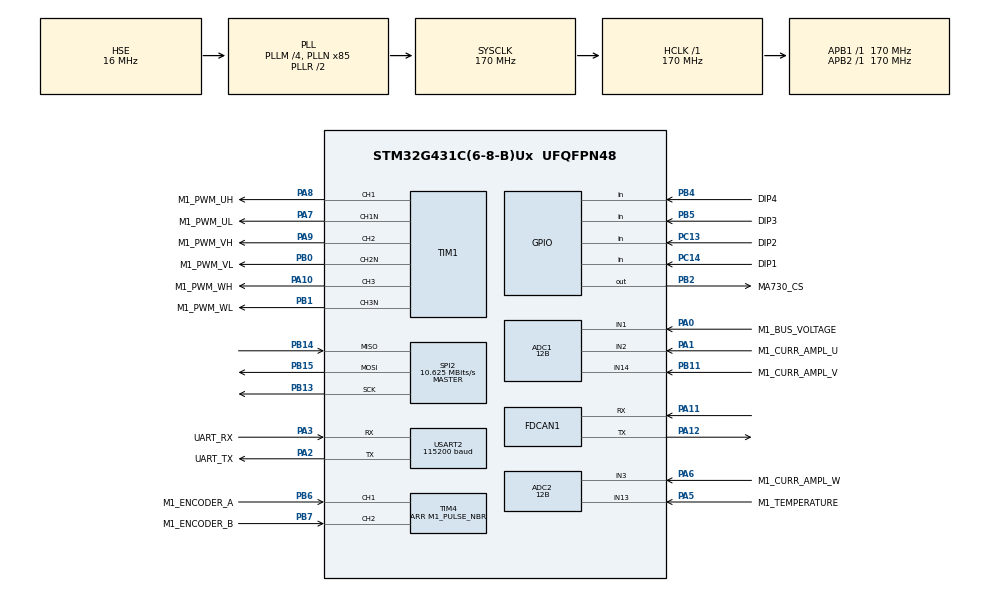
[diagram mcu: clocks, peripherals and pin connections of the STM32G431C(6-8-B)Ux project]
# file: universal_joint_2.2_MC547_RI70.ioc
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ADC1.Channel-1\#ChannelRegularConversion=ADC_CHANNEL_1
ADC1.ClockPrescaler=ADC_CLOCK_ASYNC_DIV4
ADC1.ContinuousConvMode=DISABLE
ADC1.DMAContinuousRequests=DISABLE
ADC1.DataAlign=ADC_DATAALIGN_LEFT
ADC1.DiscontinuousConvMode=DISABLE
ADC1.EOCSelection=ADC_EOC_SINGLE_CONV
ADC1.EnableAnalogWatchDog1=false
ADC1.EnableAnalogWatchDog2=false
ADC1.EnableAnalogWatchDog3=false
ADC1.EnableInjectedConversion=ENABLE
ADC1.EnableRegularConversion=ENABLE
ADC1.ExternalTrigConv=ADC_SOFTWARE_START
ADC1.ExternalTrigConvEdge=ADC_EXTERNALTRIGCONVEDGE_NONE
ADC1.ExternalTrigInjecConv=ADC_EXTERNALTRIGINJEC_T1_TRGO
ADC1.ExternalTrigInjecConvEdge=ADC_EXTERNALTRIGINJECCONV_EDGE_RISING
ADC1.InjNumberOfConversion=2
ADC1.InjectedChannel-1\#ChannelInjectedConversion=ADC_CHANNEL_2
ADC1.InjectedChannel-2\#ChannelInjectedConversion=ADC_CHANNEL_14
ADC1.InjectedConvMode=None
ADC1.InjectedOffset-1\#ChannelInjectedConversion=0
ADC1.InjectedOffset-2\#ChannelInjectedConversion=0
ADC1.InjectedOffsetNumber-1\#ChannelInjectedConversion=ADC_OFFSET_NONE
ADC1.InjectedOffsetNumber-2\#ChannelInjectedConversion=ADC_OFFSET_NONE
ADC1.InjectedRank-1\#ChannelInjectedConversion=1
ADC1.InjectedRank-2\#ChannelInjectedConversion=2
ADC1.InjectedSamplingTime-1\#ChannelInjectedConversion=ADC_SAMPLETIME_6CYCLES_5
ADC1.InjectedSamplingTime-2\#ChannelInjectedConversion=ADC_SAMPLETIME_6CYCLES_5
ADC1.LowPowerAutoWait=DISABLE
ADC1.NbrOfConversion=1
ADC1.NbrOfConversionFlag=1
ADC1.Offset-1\#ChannelRegularConversion=0
ADC1.OffsetNumber-1\#ChannelRegularConversion=ADC_OFFSET_NONE
ADC1.Overrun=ADC_OVR_DATA_PRESERVED
ADC1.Rank-1\#ChannelRegularConversion=1
ADC1.Resolution=ADC_RESOLUTION_12B
ADC1.SamplingTime-1\#ChannelRegularConversion=ADC_SAMPLETIME_47CYCLES_5
ADC1.ScanConvMode=ADC_SCAN_ENABLE
ADC1.master=1
ADC2.Channel-1\#ChannelRegularConversion=ADC_CHANNEL_13
ADC2.ClockPrescaler=ADC_CLOCK_ASYNC_DIV4
ADC2.ContinuousConvMode=DISABLE
ADC2.DMAContinuousRequests=DISABLE
ADC2.DataAlign=ADC_DATAALIGN_LEFT
ADC2.DiscontinuousConvMode=DISABLE
ADC2.EOCSelection=ADC_EOC_SINGLE_CONV
ADC2.EnableAnalogWatchDog1=false
ADC2.EnableAnalogWatchDog2=false
ADC2.EnableAnalogWatchDog3=false
ADC2.EnableInjectedConversion=ENABLE
ADC2.EnableRegularConversion=ENABLE
ADC2.ExternalTrigConv=ADC_SOFTWARE_START
ADC2.ExternalTrigConvEdge=ADC_EXTERNALTRIGCONVEDGE_NONE
ADC2.ExternalTrigInjecConv=ADC_EXTERNALTRIGINJEC_T1_TRGO
ADC2.ExternalTrigInjecConvEdge=ADC_EXTERNALTRIGINJECCONV_EDGE_RISING
ADC2.InjNumberOfConversion=2
ADC2.InjectedChannel-1\#ChannelInjectedConversion=ADC_CHANNEL_14
ADC2.InjectedChannel-2\#ChannelInjectedConversion=ADC_CHANNEL_3
ADC2.InjectedConvMode=None
ADC2.InjectedOffset-1\#ChannelInjectedConversion=0
ADC2.InjectedOffset-2\#ChannelInjectedConversion=0
ADC2.InjectedOffsetNumber-1\#ChannelInjectedConversion=ADC_OFFSET_NONE
ADC2.InjectedOffsetNumber-2\#ChannelInjectedConversion=ADC_OFFSET_NONE
ADC2.InjectedRank-1\#ChannelInjectedConversion=1
ADC2.InjectedRank-2\#ChannelInjectedConversion=2
ADC2.InjectedSamplingTime-1\#ChannelInjectedConversion=ADC_SAMPLETIME_6CYCLES_5
ADC2.InjectedSamplingTime-2\#ChannelInjectedConversion=ADC_SAMPLETIME_6CYCLES_5
ADC2.LowPowerAutoWait=DISABLE
ADC2.NbrOfConversion=1
ADC2.NbrOfConversionFlag=1
ADC2.Offset-1\#ChannelRegularConversion=0
ADC2.OffsetNumber-1\#ChannelRegularConversion=ADC_OFFSET_NONE
ADC2.Overrun=ADC_OVR_DATA_PRESERVED
ADC2.Rank-1\#ChannelRegularConversion=1
ADC2.Resolution=ADC_RESOLUTION_12B
ADC2.SamplingTime-1\#ChannelRegularConversion=ADC_SAMPLETIME_47CYCLES_5
ADC2.ScanConvMode=ADC_SCAN_ENABLE
ADC2.master=1
Dma.Request0=SPI2_RX
Dma.Request1=SPI2_TX
Dma.SPI2_RX.0.Direction=DMA_PERIPH_TO_MEMORY
Dma.SPI2_RX.0.EventEnable=DISABLE
Dma.SPI2_RX.0.Instance=DMA1_Channel1
Dma.SPI2_RX.0.MemDataAlignment=DMA_MDATAALIGN_HALFWORD
Dma.SPI2_RX.0.MemInc=DMA_MINC_ENABLE
Dma.SPI2_RX.0.Mode=DMA_NORMAL
Dma.SPI2_RX.0.PeriphDataAlignment=DMA_PDATAALIGN_HALFWORD
Dma.SPI2_RX.0.PeriphInc=DMA_PINC_DISABLE
Dma.SPI2_RX.0.Polarity=HAL_DMAMUX_REQ_GEN_RISING
Dma.SPI2_RX.0.Priority=DMA_PRIORITY_LOW
Dma.SPI2_RX.0.RequestNumber=1
Dma.SPI2_RX.0.SignalID=NONE
Dma.SPI2_RX.0.SyncEnable=DISABLE
Dma.SPI2_RX.0.SyncPolarity=HAL_DMAMUX_SYNC_NO_EVENT
Dma.SPI2_RX.0.SyncRequestNumber=1
Dma.SPI2_RX.0.SyncSignalID=NONE
Dma.SPI2_TX.1.Direction=DMA_MEMORY_TO_PERIPH
Dma.SPI2_TX.1.EventEnable=DISABLE
Dma.SPI2_TX.1.Instance=DMA1_Channel2
Dma.SPI2_TX.1.MemDataAlignment=DMA_MDATAALIGN_HALFWORD
Dma.SPI2_TX.1.MemInc=DMA_MINC_ENABLE
Dma.SPI2_TX.1.Mode=DMA_NORMAL
Dma.SPI2_TX.1.PeriphDataAlignment=DMA_PDATAALIGN_HALFWORD
Dma.SPI2_TX.1.PeriphInc=DMA_PINC_DISABLE
Dma.SPI2_TX.1.Polarity=HAL_DMAMUX_REQ_GEN_RISING
Dma.SPI2_TX.1.Priority=DMA_PRIORITY_LOW
Dma.SPI2_TX.1.RequestNumber=1
Dma.SPI2_TX.1.SignalID=NONE
Dma.SPI2_TX.1.SyncEnable=DISABLE
Dma.SPI2_TX.1.SyncPolarity=HAL_DMAMUX_SYNC_NO_EVENT
Dma.SPI2_TX.1.SyncRequestNumber=1
Dma.SPI2_TX.1.SyncSignalID=NONE
ExtraMW=MotorControl
ExtraMW.MotorControl.Config=MotorControl
ExtraMW.MotorControl.Mode=MotorControl
ExtraMW.MotorControl.Root=MCSDK_v5.4.7/MotorControl
ExtraMW.MotorControl.Template=templates
FDCAN1.AutoRetransmission=ENABLE
FDCAN1.ClockDivider=FDCAN_CLOCK_DIV2
FDCAN1.DataSyncJumpWidth=2
FDCAN1.DataTimeSeg1=12
FDCAN1.DataTimeSeg2=4
FDCAN1.FrameFormat=FDCAN_FRAME_FD_BRS
FDCAN1.NominalPrescaler=5
FDCAN1.NominalSyncJumpWidth=2
FDCAN1.NominalTimeSeg1=12
FDCAN1.NominalTimeSeg2=4
FDCAN1.StdFiltersNbr=2
FDCAN1.TransmitPause=ENABLE
Mcu.Family=STM32G4
Mcu.Name=STM32G431C(6-8-B)Ux
Mcu.Package=UFQFPN48
MotorControl.ADC_1_PERIPH=ADC1
MotorControl.ADC_2_PERIPH=ADC2
MotorControl.ADC_AHBPERIPH=RCC_AHBPeriph_ADC12
MotorControl.ADC_CLOCK_WB_DIV=4
MotorControl.ADC_CLOCK_WB_FREQ=42.5
MotorControl.ADC_PERIPH=ADC1
MotorControl.ADC_REFERENCE_VOLTAGE=3.30
MotorControl.ALIGNMENT_ANGLE_DEG=90
MotorControl.ALIGNMENT_DURATION=700
MotorControl.AMPLIFICATION_GAIN=5.00
MotorControl.ANGC={0,0,0,0,0,0,0,0}
MotorControl.BEMF_CONSISTENCY_GAIN=64
MotorControl.BEMF_CONSISTENCY_TOL=64
MotorControl.BKIN1_FILTER=0
MotorControl.BKIN2_FILTER=0
MotorControl.BKIN2_MODE=NONE
MotorControl.BKIN_MODE=NONE
MotorControl.BOARD=CUSTOM
MotorControl.BRKIN2_GPIO_AF=GPIO_AF_12
MotorControl.BRKIN_GPIO_AF=GPIO_AF_2
MotorControl.BUS_VOLTAGE_READING=true
MotorControl.CCMRAM_ENABLED=false
MotorControl.CLOCK_FREQUENCY=CPU_CLK_170_MHZ
MotorControl.CLOCK_SOURCE=EXTERNAL
MotorControl.CONSTANT1_D=500971
MotorControl.CONSTANT1_Q=500971
MotorControl.CONSTANT2_QD=39758
MotorControl.CORD_BEMF_CONSISTENCY_GAIN=64
MotorControl.CORD_BEMF_CONSISTENCY_TOL=64
MotorControl.CORD_F1=16384
MotorControl.CORD_F2=4096
MotorControl.CORD_FIFO_DEPTH_01HZ=64
MotorControl.CORD_FIFO_DEPTH_DPP=64
MotorControl.CORD_GAIN1=-24300
MotorControl.CORD_GAIN2=19853
MotorControl.CORD_MAX_ACCEL_DPPP=60
MotorControl.CORD_MEAS_ERRORS_BEFORE_FAULTS=3
MotorControl.CORD_VARIANCE_THRESHOLD=4
MotorControl.CPU_CLK_170_MHZ=true
MotorControl.CTRBDID=0
MotorControl.CUBE_MX_VER=6.3.0
MotorControl.CURRENT_READING_TOPOLOGY=THREE_SHUNT_INDEPENDENT_RESOURCES
MotorControl.CURR_SAMPLING_TIME=6
MotorControl.DAC_EMULATED=false
MotorControl.DAC_FUNCTIONALITY=false
MotorControl.DAC_TIMER_CH1_GPIO_PIN=LL_GPIO_PIN_0
MotorControl.DAC_TIMER_CH1_GPIO_PORT=GPIOA
MotorControl.DAC_TIMER_CH2_GPIO_PIN=LL_GPIO_PIN_0
MotorControl.DAC_TIMER_CH2_GPIO_PORT=GPIOA
MotorControl.DAC_TIMER_SELECTION=TIM3
MotorControl.DC_CURRENT_RS_MEAS=16.80
MotorControl.DEBUG_DAC_CH1=false
MotorControl.DEBUG_DAC_CH2=false
MotorControl.DEFAULT_CONTROL_MODE=STC_TORQUE_MODE
MotorControl.DEFAULT_DAC_CHANNEL_1=MC_PROTOCOL_REG_I_A
MotorControl.DEFAULT_DAC_CHANNEL_2=MC_PROTOCOL_REG_I_B
MotorControl.DEFAULT_DAC_MOTOR=0
MotorControl.DEFAULT_FLUX_COMPONENT=0
MotorControl.DEFAULT_TARGET_SPEED_RPM=1500
MotorControl.DEFAULT_TORQUE_COMPONENT=0
MotorControl.DISSIPATIVE_BRAKE_POLARITY=DOUT_ACTIVE_HIGH
MotorControl.DRIVES_NUMBER_SELECTION=SINGLEDRIVE
MotorControl.EMERGENCY2_STOP_GPIO_PIN=LL_GPIO_PIN_11
MotorControl.EMERGENCY2_STOP_GPIO_PORT=GPIOA
MotorControl.EMERGENCY_STOP_GPIO_PIN=LL_GPIO_PIN_11
MotorControl.EMERGENCY_STOP_GPIO_PORT=GPIOA
MotorControl.ENABLE_SL_ALGO_FROM_PHASE=3
MotorControl.ENCODER=true
MotorControl.ENCODER_AVAILABLE=true
MotorControl.ENCODER_PPR=3584
MotorControl.ENC_AVERAGING_FIFO_DEPTH=16
MotorControl.ENC_A_GPIO_PIN=LL_GPIO_PIN_6
MotorControl.ENC_A_GPIO_PORT=GPIOB
MotorControl.ENC_B_GPIO_PIN=LL_GPIO_PIN_7
MotorControl.ENC_B_GPIO_PORT=GPIOB
MotorControl.ENC_ICx_FILTER=128
MotorControl.ENC_INVERT_SPEED=false
MotorControl.ENC_MEAS_ERRORS_BEFORE_FAULTS=3
MotorControl.ENC_TIMER_REMAPPING=NO_REMAP_TIM4
MotorControl.ENC_TIMER_SELECTION=ENC_TIM4
MotorControl.ENC_USE_CH3=false
MotorControl.EXT_CLK_8_MHZ=true
MotorControl.EXT_CLOCK_FREQUENCY=EXT_CLK_8_MHZ
MotorControl.F1=16384
MotorControl.F2=4096
MotorControl.FEEDBACK_NET_FILTERING=false
MotorControl.FEED_FORWARD_CURRENT_REG_ENABLING=false
MotorControl.FINAL_I_ALIGNMENT=1936
MotorControl.FLUX_WEAKENING_ENABLING=false
MotorControl.FW_KIDIV=32768
MotorControl.FW_KI_GAIN=5000
MotorControl.FW_KPDIV=32768
MotorControl.FW_KP_GAIN=3000
MotorControl.FW_VOLTAGE_REF=985
MotorControl.GAIN1=-24300
MotorControl.GAIN2=19853
MotorControl.H1_GPIO_PIN=LL_GPIO_PIN_15
MotorControl.H1_GPIO_PORT=GPIOA
MotorControl.H2_GPIO_PIN=LL_GPIO_PIN_3
MotorControl.H2_GPIO_PORT=GPIOB
MotorControl.H3_GPIO_PIN=LL_GPIO_PIN_10
MotorControl.H3_GPIO_PORT=GPIOB
MotorControl.HALL_AVERAGING_FIFO_DEPTH=6
MotorControl.HALL_ICx_FILTER=255
MotorControl.HALL_MEAS_ERRORS_BEFORE_FAULTS=3
MotorControl.HALL_MTPA=false
MotorControl.HALL_PHASE_SHIFT=60
MotorControl.HALL_SENSORS_AVAILABLE=false
MotorControl.HALL_SENSORS_PLACEMENT=DEGREES_120
MotorControl.HALL_TIMER_REMAPPING=NO_REMAP_TIM2
MotorControl.HALL_TIMER_SELECTION=HALL_TIM2
MotorControl.HFI_AMPLITUDE=25
MotorControl.HFI_DC_0_COEFF=0.00146
MotorControl.HFI_DC_1_COEFF=0.002921
MotorControl.HFI_DC_2_COEFF=0.00146
MotorControl.HFI_DC_3_COEFF=1.889033
MotorControl.HFI_DC_4_COEFF=-0.894874
MotorControl.HFI_DEBUG_MODE=false
MotorControl.HFI_FREQUENCY=400
MotorControl.HFI_HIFRAMPLSCAN=25
MotorControl.HFI_HP_ID_0_COEFF=0.959381
MotorControl.HFI_HP_ID_1_COEFF=-1.918761
MotorControl.HFI_HP_ID_2_COEFF=0.959381
MotorControl.HFI_HP_ID_3_COEFF=1.917111
MotorControl.HFI_HP_ID_4_COEFF=-0.920412
MotorControl.HFI_IDH_DELAY=32400
MotorControl.HFI_LOCKFREQ=22
MotorControl.HFI_LP_ID_0_COEFF=0.002751
MotorControl.HFI_LP_ID_1_COEFF=0.005502
MotorControl.HFI_LP_ID_2_COEFF=0.002751
MotorControl.HFI_LP_ID_3_COEFF=1.846252
MotorControl.HFI_LP_ID_4_COEFF=-0.857255
MotorControl.HFI_MAXANGLEDIFF=3640
MotorControl.HFI_MINIMUM_SPEED_RPM=402
MotorControl.HFI_NOTCH_IQD_0_COEFF=0.979509
MotorControl.HFI_NOTCH_IQD_1_COEFF=-1.952148
MotorControl.HFI_NOTCH_IQD_2_COEFF=0.979509
MotorControl.HFI_NOTCH_IQD_3_COEFF=1.952148
MotorControl.HFI_NOTCH_IQD_4_COEFF=-0.959018
MotorControl.HFI_NSDETPOINTSSKIP=10
MotorControl.HFI_NSMAXDETPOINTS=20
MotorControl.HFI_NS_MIN_SAT_DIFF=0
MotorControl.HFI_PID_KIDIV=32768
MotorControl.HFI_PID_KI_DEFAULT=400
MotorControl.HFI_PID_KPDIV=16384
MotorControl.HFI_PID_KP_DEFAULT=800
MotorControl.HFI_PLL_KI_DEFAULT=0.00400
MotorControl.HFI_PLL_KP_DEFAULT=0.00060
MotorControl.HFI_RESTARTTIMESEC=0.1
MotorControl.HFI_RESTART_RPM_TH=(((HFI_STO_RPM_TH)+(STO_HFI_RPM_TH))/2)
MotorControl.HFI_REVERT_DIRECTION=true
MotorControl.HFI_SCANROTATIONSNO=3
MotorControl.HFI_SPD_BUFFER_DEPTH_01HZ=64
MotorControl.HFI_STEPANGLE=3640
MotorControl.HFI_STO_RPM_TH=OBS_MINIMUM_SPEED_RPM
MotorControl.HFI_WAITAFTERNS2=4
MotorControl.HFI_WAITBEFORESN=6
MotorControl.HFI_WAITSYNCH=20
MotorControl.HFI_WAITTRACK=20
MotorControl.HIGH_SIDE_BRAKE_STATE=false
MotorControl.HIGH_SIDE_IDLE_STATE=false
MotorControl.HW_COMPLEMENTED_LOW_SIDE=false
MotorControl.HW_DEAD_TIME_NS=100
MotorControl.HW_OV_CURRENT_PROT_BYPASS=false
MotorControl.ID_DEMAG=-16681
MotorControl.INRUSH_CURRLIMIT_AT_POWER_ON=true
MotorControl.INRUSH_CURRLIMIT_CHANGE_AFTER_MS=1000
MotorControl.INRUSH_CURRLIMIT_ENABLING=false
MotorControl.INRUSH_CURRLIMIT_GPIO_PIN=LL_GPIO_PIN_4
MotorControl.INRUSH_CURRLIMIT_GPIO_PORT=GPIOE
MotorControl.INRUSH_CURR_LIMITER_POLARITY=DOUT_ACTIVE_HIGH
MotorControl.INTERNAL_OVERCURRENTPROTECTION=false
MotorControl.INTERNAL_OVERVOLTAGEPROTECTION=false
MotorControl.IPs=CORDIC,NVIC,RCC,SYS,MotorControl,TIM1,ADC1,ADC2,TIM4,USART2
MotorControl.IQMAX=16681
MotorControl.LCD_JOYSTICK_FUNCTIONALITY=false
MotorControl.LCD_MODE=LCD_FULL
MotorControl.LDLQ_RATIO=1.000
MotorControl.LOW_SIDE_BRAKE_STATE=false
MotorControl.LOW_SIDE_IDLE_STATE=false
MotorControl.LOW_SIDE_SIGNALS_ENABLING=LS_PWM_TIMER
MotorControl.LS=0.000311
MotorControl.MAX_APPLICATION_SPEED=3125
MotorControl.MAX_MODULATION_81_PER_CENT=true
MotorControl.MAX_MODULATION_INDEX=MAX_MODULATION_81_PER_CENT
MotorControl.MCU=STM32G431CB
MotorControl.MCU_TYPE=STM32G431CB
MotorControl.MC_WORKBENCH_VERSION=5.4.7.21279
MotorControl.MEAS_ERRORS_BEFORE_FAULTS=3
MotorControl.MIN_APPLICATION_SPEED=0
MotorControl.MOTOR_MAX_SPEED_RPM=3125
MotorControl.MOTOR_TYPE=PMSM
MotorControl.MOTOR_VOLTAGE_CONSTANT=11.7
MotorControl.MTPA_ENABLING=false
MotorControl.NB_CONSECUTIVE_TESTS=2
MotorControl.NOMINAL_BUS_VOLTAGE_V=48
MotorControl.NOMINAL_CURRENT=16681
MotorControl.OBS_MEAS_ERRORS_BEFORE_FAULTS=3
MotorControl.OBS_MINIMUM_SPEED_RPM=580
MotorControl.OCPA_INVERTINGINPUT=COMPX_InvertingInput_VREF
MotorControl.OCPA_INVERTINGINPUT_GPIO_PIN=LL_GPIO_PIN_4
MotorControl.OCPA_INVERTINGINPUT_GPIO_PORT=GPIOA
MotorControl.OCPA_INVERTINGINPUT_MODE=INT_MODE
MotorControl.OCPA_NONINVERTINGINPUT=COMP1_NonInvertingInput_PA1
MotorControl.OCPA_NONINVERTINGINPUT_GPIO_PIN=LL_GPIO_PIN_1
MotorControl.OCPA_NONINVERTINGINPUT_GPIO_PORT=GPIOA
MotorControl.OCPA_OUTPUT=COMP_Output_TIM1BKIN2
MotorControl.OCPA_OUTPUTPOL=COMP_OutputPol_NonInverted
MotorControl.OCPA_OUTPUT_GPIO_AF=GPIO_AF_2
MotorControl.OCPA_OUTPUT_GPIO_PIN=LL_GPIO_PIN_0
MotorControl.OCPA_OUTPUT_GPIO_PORT=GPIOA
MotorControl.OCPA_OUTPUT_MODE=INT_MODE
MotorControl.OCPA_SELECTION=COMP1
MotorControl.OCPB_INVERTINGINPUT=COMPX_InvertingInput_VREF
MotorControl.OCPB_INVERTINGINPUT_GPIO_PIN=LL_GPIO_PIN_4
MotorControl.OCPB_INVERTINGINPUT_GPIO_PORT=GPIOA
MotorControl.OCPB_INVERTINGINPUT_MODE=INT_MODE
MotorControl.OCPB_NONINVERTINGINPUT=COMP2_NonInvertingInput_PA7
MotorControl.OCPB_NONINVERTINGINPUT_GPIO_PIN=LL_GPIO_PIN_7
MotorControl.OCPB_NONINVERTINGINPUT_GPIO_PORT=GPIOA
MotorControl.OCPB_OUTPUT=COMP_Output_TIM1BKIN2
MotorControl.OCPB_OUTPUTPOL=COMP_OutputPol_NonInverted
MotorControl.OCPB_OUTPUT_GPIO_AF=GPIO_AF_2
MotorControl.OCPB_OUTPUT_GPIO_PIN=LL_GPIO_PIN_2
MotorControl.OCPB_OUTPUT_GPIO_PORT=GPIOA
MotorControl.OCPB_OUTPUT_MODE=INT_MODE
MotorControl.OCPB_SELECTION=COMP2
MotorControl.OCPC_INVERTINGINPUT=COMPX_InvertingInput_VREF
MotorControl.OCPC_INVERTINGINPUT_GPIO_PIN=LL_GPIO_PIN_4
MotorControl.OCPC_INVERTINGINPUT_GPIO_PORT=GPIOA
MotorControl.OCPC_INVERTINGINPUT_MODE=INT_MODE
MotorControl.OCPC_NONINVERTINGINPUT=COMP3_NonInvertingInput_PD14
MotorControl.OCPC_NONINVERTINGINPUT_GPIO_PIN=LL_GPIO_PIN_14
MotorControl.OCPC_NONINVERTINGINPUT_GPIO_PORT=GPIOD
MotorControl.OCPC_OUTPUT=COMP_Output_TIM1BKIN2
MotorControl.OCPC_OUTPUTPOL=COMP_OutputPol_NonInverted
MotorControl.OCPC_OUTPUT_GPIO_AF=GPIO_AF_2
MotorControl.OCPC_OUTPUT_GPIO_PIN=LL_GPIO_PIN_8
MotorControl.OCPC_OUTPUT_GPIO_PORT=GPIOC
MotorControl.OCPC_OUTPUT_MODE=INT_MODE
MotorControl.OCPC_SELECTION=COMP3
MotorControl.OCPREF=23830
MotorControl.OCP_COMP_THRESHOLD=0.50
MotorControl.OCP_FILTER=COMP_Mode_HighSpeed
MotorControl.OCP_INVERTINGINPUT=COMPX_InvertingInput_VREF
MotorControl.OCP_INVERTINGINPUT_GPIO_PIN=LL_GPIO_PIN_4
MotorControl.OCP_INVERTINGINPUT_GPIO_PORT=GPIOA
MotorControl.OCP_INVERTINGINPUT_MODE=INT_MODE
MotorControl.OCP_NONINVERTINGINPUT=COMP2_NonInvertingInput_PA7
MotorControl.OCP_NONINVERTINGINPUT_GPIO_PIN=LL_GPIO_PIN_7
MotorControl.OCP_NONINVERTINGINPUT_GPIO_PORT=GPIOA
MotorControl.OCP_OUTPUT=COMP_Output_TIM1BKIN2
MotorControl.OCP_OUTPUTPOL=COMP_OutputPol_NonInverted
MotorControl.OCP_OUTPUT_GPIO_AF=GPIO_AF_2
MotorControl.OCP_OUTPUT_GPIO_PIN=LL_GPIO_PIN_2
MotorControl.OCP_OUTPUT_GPIO_PORT=GPIOA
MotorControl.OCP_OUTPUT_MODE=INT_MODE
MotorControl.OCP_SELECTION=COMP2
MotorControl.OFST={0,0,0,0,0,0,0,0}
MotorControl.ON_OVER_VOLTAGE=TURN_ON_LOW_SIDES
MotorControl.OPAMP1_INVERTINGINPUT=OPAMP1_InvertingInput_PGA
MotorControl.OPAMP1_INVERTINGINPUT_GPIO_PIN=LL_GPIO_PIN_3
MotorControl.OPAMP1_INVERTINGINPUT_GPIO_PORT=GPIOA
MotorControl.OPAMP1_INVERTINGINPUT_MODE=INT_MODE
MotorControl.OPAMP1_NONINVERTINGINPUT_PHA=OPAMP1_NonInvertingInput_PA1
MotorControl.OPAMP1_NONINVERTINGINPUT_PHA_GPIO_PIN=LL_GPIO_PIN_1
MotorControl.OPAMP1_NONINVERTINGINPUT_PHA_GPIO_PORT=GPIOA
MotorControl.OPAMP1_NONINVERTINGINPUT_PHB=OPAMP1_NonInvertingInput_PA7
MotorControl.OPAMP1_NONINVERTINGINPUT_PHB_GPIO_PIN=LL_GPIO_PIN_7
MotorControl.OPAMP1_NONINVERTINGINPUT_PHB_GPIO_PORT=GPIOA
MotorControl.OPAMP1_OUT_GPIO_PIN=LL_GPIO_PIN_2
MotorControl.OPAMP1_OUT_GPIO_PORT=GPIOA
MotorControl.OPAMP1_SELECTION=OPAMP1
MotorControl.OPAMP2_INVERTINGINPUT=OPAMP2_InvertingInput_PGA
MotorControl.OPAMP2_INVERTINGINPUT_GPIO_PIN=LL_GPIO_PIN_5
MotorControl.OPAMP2_INVERTINGINPUT_GPIO_PORT=GPIOC
MotorControl.OPAMP2_INVERTINGINPUT_MODE=INT_MODE
MotorControl.OPAMP2_NONINVERTINGINPUT_PHA=OPAMP2_NonInvertingInput_PB14
MotorControl.OPAMP2_NONINVERTINGINPUT_PHA_GPIO_PIN=LL_GPIO_PIN_14
MotorControl.OPAMP2_NONINVERTINGINPUT_PHA_GPIO_PORT=GPIOB
MotorControl.OPAMP2_NONINVERTINGINPUT_PHB=OPAMP2_NonInvertingInput_PA7
MotorControl.OPAMP2_NONINVERTINGINPUT_PHB_GPIO_PIN=LL_GPIO_PIN_7
MotorControl.OPAMP2_NONINVERTINGINPUT_PHB_GPIO_PORT=GPIOA
MotorControl.OPAMP2_NONINVERTINGINPUT_PHC=OPAMP2_NonInvertingInput_PB14
MotorControl.OPAMP2_NONINVERTINGINPUT_PHC_GPIO_PIN=LL_GPIO_PIN_14
MotorControl.OPAMP2_NONINVERTINGINPUT_PHC_GPIO_PORT=GPIOB
MotorControl.OPAMP2_OUT_GPIO_PIN=LL_GPIO_PIN_6
MotorControl.OPAMP2_OUT_GPIO_PORT=GPIOA
MotorControl.OPAMP2_SELECTION=OPAMP2
MotorControl.OPAMP3_INVERTINGINPUT=OPAMP1_InvertingInput_PGA
MotorControl.OPAMP3_INVERTINGINPUT_GPIO_PIN=LL_GPIO_PIN_0
MotorControl.OPAMP3_INVERTINGINPUT_GPIO_PORT=GPIOA
MotorControl.OPAMP3_INVERTINGINPUT_MODE=INT_MODE
MotorControl.OPAMP3_SELECTION=OPAMP1
MotorControl.OPAMP_INVERTINGINPUT=OPAMP1_InvertingInput_PGA
MotorControl.OPAMP_INVERTINGINPUT_GPIO_PIN=LL_GPIO_PIN_3
MotorControl.OPAMP_INVERTINGINPUT_GPIO_PORT=GPIOA
MotorControl.OPAMP_INVERTINGINPUT_MODE=INT_MODE
MotorControl.OPAMP_NONINVERTINGINPUT=OPAMP1_NonInvertingInput_PA7
MotorControl.OPAMP_NONINVERTINGINPUT_GPIO_PIN=LL_GPIO_PIN_7
MotorControl.OPAMP_NONINVERTINGINPUT_GPIO_PORT=GPIOA
MotorControl.OPAMP_OUT_GPIO_PIN=LL_GPIO_PIN_2
MotorControl.OPAMP_OUT_GPIO_PORT=GPIOA
MotorControl.OPAMP_PGACONNECT=OPAMP_PGAConnect_No
MotorControl.OPAMP_PGAGAIN=OPAMP_OPAMP_PGAGain_2
MotorControl.OPAMP_SELECTION=OPAMP1
MotorControl.OPAMP_TYPE_GAIN=INTERNAL
MotorControl.OPEN_LOOP_FOC=false
MotorControl.OPEN_LOOP_K=44
MotorControl.OPEN_LOOP_OFF=4400
MotorControl.OPEN_LOOP_SPEED_RAMP_DURATION_MS=1000
MotorControl.OPEN_LOOP_SPEED_RPM=100
MotorControl.OPEN_LOOP_VF=false
MotorControl.OPEN_LOOP_VOLTAGE_d=6000
MotorControl.OVERCURR_FEEDBACK_POLARITY=EMSTOP_ACTIVE_LOW
MotorControl.OVERCURR_PROTECTION_HW_DISABLING=DOUT_ACTIVE_HIGH
MotorControl.OVPREF=23830
MotorControl.OVP_FILTER=COMP_Mode_HighSpeed
MotorControl.OVP_INVERTINGINPUT=COMPX_InvertingInput_VREF
MotorControl.OVP_INVERTINGINPUT_GPIO_PIN=LL_GPIO_PIN_4
MotorControl.OVP_INVERTINGINPUT_GPIO_PORT=GPIOA
MotorControl.OVP_INVERTINGINPUT_MODE=INT_MODE
MotorControl.OVP_NONINVERTINGINPUT=COMP7_NonInvertingInput_PA0
MotorControl.OVP_NONINVERTINGINPUT_GPIO_PIN=LL_GPIO_PIN_0
MotorControl.OVP_NONINVERTINGINPUT_GPIO_PORT=GPIOA
MotorControl.OVP_OUTPUT=COMP_Output_TIM1BKIN
MotorControl.OVP_OUTPUTPOL=COMP_OutputPol_NonInverted
MotorControl.OVP_OUTPUT_GPIO_AF=GPIO_AF_2
MotorControl.OVP_OUTPUT_GPIO_PIN=LL_GPIO_PIN_2
MotorControl.OVP_OUTPUT_GPIO_PORT=GPIOC
MotorControl.OVP_OUTPUT_MODE=INT_MODE
MotorControl.OVP_SELECTION=COMP7
MotorControl.OV_CURR_BYPASS_GPIO_PIN=LL_GPIO_PIN_5
MotorControl.OV_CURR_BYPASS_GPIO_PORT=GPIOE
MotorControl.OV_TEMPERATURE_HYSTERESIS_C=10
MotorControl.OV_TEMPERATURE_PROT_ENABLING=true
MotorControl.OV_TEMPERATURE_THRESHOLD_C=80
MotorControl.OV_VOLTAGE_PROT_ENABLING=true
MotorControl.OV_VOLTAGE_THRESHOLD_V=75
MotorControl.PHASE1_DURATION=0
MotorControl.PHASE1_FINAL_CURRENT=0
MotorControl.PHASE1_FINAL_SPEED_RPM=0
MotorControl.PHASE2_DURATION=700
MotorControl.PHASE2_FINAL_CURRENT=595
MotorControl.PHASE2_FINAL_SPEED_RPM=0
MotorControl.PHASE3_DURATION=350
MotorControl.PHASE3_FINAL_CURRENT=695
MotorControl.PHASE3_FINAL_SPEED_RPM=630
MotorControl.PHASE4_DURATION=1150
MotorControl.PHASE4_FINAL_CURRENT=695
MotorControl.PHASE4_FINAL_SPEED_RPM=2700
MotorControl.PHASE5_DURATION=0
MotorControl.PHASE5_FINAL_CURRENT=695
MotorControl.PHASE5_FINAL_SPEED_RPM=2700
MotorControl.PHASE_CURRENTS_ADC=ADC1_2
MotorControl.PHASE_CURRENTS_CHANNEL=ADC_CHANNEL_9
MotorControl.PHASE_CURRENTS_GPIO_PIN=LL_GPIO_PIN_0
MotorControl.PHASE_CURRENTS_GPIO_PORT=GPIOA
MotorControl.PHASE_UH_GPIO_AF=GPIO_AF_6
MotorControl.PHASE_UH_GPIO_PIN=LL_GPIO_PIN_8
MotorControl.PHASE_UH_GPIO_PORT=GPIOA
MotorControl.PHASE_UH_POLARITY=H_ACTIVE_HIGH
MotorControl.PHASE_UL_GPIO_AF=GPIO_AF_6
MotorControl.PHASE_UL_GPIO_PIN=LL_GPIO_PIN_7
MotorControl.PHASE_UL_GPIO_PORT=GPIOA
MotorControl.PHASE_UL_POLARITY=L_ACTIVE_HIGH
MotorControl.PHASE_U_CURR_ADC=ADC1_2
MotorControl.PHASE_U_CURR_CHANNEL=ADC_CHANNEL_2
MotorControl.PHASE_U_GPIO_PIN=LL_GPIO_PIN_1
MotorControl.PHASE_U_GPIO_PORT=GPIOA
MotorControl.PHASE_VH_GPIO_AF=GPIO_AF_6
MotorControl.PHASE_VH_GPIO_PIN=LL_GPIO_PIN_9
MotorControl.PHASE_VH_GPIO_PORT=GPIOA
MotorControl.PHASE_VH_POLARITY=H_ACTIVE_HIGH
MotorControl.PHASE_VL_GPIO_AF=GPIO_AF_6
MotorControl.PHASE_VL_GPIO_PIN=LL_GPIO_PIN_0
MotorControl.PHASE_VL_GPIO_PORT=GPIOB
MotorControl.PHASE_VL_POLARITY=L_ACTIVE_HIGH
MotorControl.PHASE_V_CURR_ADC=ADC1_2
MotorControl.PHASE_V_CURR_CHANNEL=ADC_CHANNEL_14
MotorControl.PHASE_V_GPIO_PIN=LL_GPIO_PIN_11
MotorControl.PHASE_V_GPIO_PORT=GPIOB
MotorControl.PHASE_WH_GPIO_AF=GPIO_AF_6
MotorControl.PHASE_WH_GPIO_PIN=LL_GPIO_PIN_10
MotorControl.PHASE_WH_GPIO_PORT=GPIOA
MotorControl.PHASE_WH_POLARITY=H_ACTIVE_HIGH
MotorControl.PHASE_WL_GPIO_AF=GPIO_AF_4
MotorControl.PHASE_WL_GPIO_PIN=LL_GPIO_PIN_1
MotorControl.PHASE_WL_GPIO_PORT=GPIOB
MotorControl.PHASE_WL_POLARITY=L_ACTIVE_HIGH
MotorControl.PHASE_W_CURR_ADC=ADC2
MotorControl.PHASE_W_CURR_CHANNEL=ADC_CHANNEL_3
MotorControl.PHASE_W_GPIO_PIN=LL_GPIO_PIN_6
MotorControl.PHASE_W_GPIO_PORT=GPIOA
MotorControl.PID_FLUX_KD_DEFAULT=100
MotorControl.PID_FLUX_KI_DEFAULT=79
MotorControl.PID_FLUX_KP_DEFAULT=3503
MotorControl.PID_SPEED_KD_DEFAULT=0
MotorControl.PID_SPEED_KI_DEFAULT=2011
MotorControl.PID_SPEED_KP_DEFAULT=3261
MotorControl.PID_TORQUE_KD_DEFAULT=100
MotorControl.PID_TORQUE_KI_DEFAULT=79
MotorControl.PID_TORQUE_KP_DEFAULT=3503
MotorControl.PLL_KI_GAIN=18
MotorControl.PLL_KP_GAIN=776
MotorControl.POLE_PAIR_NUM=14
MotorControl.POSITION_CTRL_ENABLING=false
MotorControl.PWBDID=0
MotorControl.PWM_FREQUENCY=30000
MotorControl.PWM_TIMER_REMAPPING=PWM_NO_REMAP
MotorControl.PWM_TIMER_SELECTION=PWM_TIM1
MotorControl.REGCONVADC=ADC1
MotorControl.REGULATION_EXECUTION_RATE=1
MotorControl.RS=0.21
MotorControl.RSHUNT=0.01000
MotorControl.RTOS=NONE
MotorControl.R_BRAKE_GPIO_PIN=LL_GPIO_PIN_5
MotorControl.R_BRAKE_GPIO_PORT=GPIOE
MotorControl.R_BRAKE_SWITCH_OFF_THRES_V=60
MotorControl.SEGDIV=0
MotorControl.SERIAL_COMMUNICATION=true
MotorControl.SERIAL_COM_CHANNEL1=MC_PROTOCOL_REG_I_A
MotorControl.SERIAL_COM_CHANNEL2=MC_PROTOCOL_REG_I_A
MotorControl.SERIAL_COM_MODE=COM_BIDIRECTIONAL
MotorControl.SERIAL_COM_MOTOR=0
MotorControl.SHARED_SIGNAL_ENABLE=false
MotorControl.SINGLEDRIVE=true
MotorControl.SPD_DIFFERENTIAL_TERM_ENABLING=false
MotorControl.SPEED_BAND_LOWER_LIMIT=15
MotorControl.SPEED_BAND_UPPER_LIMIT=17
MotorControl.SPEED_LOOP_FREQUENCY_HZ=1000
MotorControl.SPEED_SENSOR_SELECTION=ENCODER
MotorControl.SP_KDDIV=16
MotorControl.SP_KIDIV=16384
MotorControl.SP_KPDIV=64
MotorControl.STARTING_ANGLE_DEG=90
MotorControl.START_STOP_BTN=false
MotorControl.START_STOP_GPIO_PIN=LL_GPIO_PIN_6
MotorControl.START_STOP_GPIO_PORT=GPIOE
MotorControl.START_STOP_POLARITY=DIN_ACTIVE_LOW
MotorControl.START_STOP_POLARITY_EDGE=GPIO_NOPULL
MotorControl.STM32G431CB=true
MotorControl.STO_FIFO_DEPTH_01HZ=64
MotorControl.STO_FIFO_DEPTH_DPP=64
MotorControl.STO_HFI_RPM_TH=460
MotorControl.SW_DEADTIME_NS=800
MotorControl.SW_OV_CURRENT_PROT_ENABLING=false
MotorControl.T0_C=25
MotorControl.TEMPERATURE_READING=true
MotorControl.TEMP_ADC_SAMPLING_TIME=47
MotorControl.TEMP_FDBK_ADC=ADC2
MotorControl.TEMP_FDBK_CHANNEL=ADC_CHANNEL_13
MotorControl.TEMP_FDBK_GPIO_PIN=LL_GPIO_PIN_5
MotorControl.TEMP_FDBK_GPIO_PORT=GPIOA
MotorControl.TFDIFFERENTIAL_TERM_ENABLING=false
MotorControl.TF_KDDIV=8192
MotorControl.TF_KIDIV=16384
MotorControl.TF_KPDIV=16384
MotorControl.THREE_SHUNT_INDEPENDENT_RESOURCES=true
MotorControl.TNOISE_NS=2550
MotorControl.TRANSITION_DURATION=25
MotorControl.TRISE_NS=2550
MotorControl.T_MAX=80
MotorControl.UD_VOLTAGE_THRESHOLD_V=20
MotorControl.USART_REMAPPING=NO_REMAP_USART2
MotorControl.USART_RX_GPIO_PIN=LL_GPIO_PIN_3
MotorControl.USART_RX_GPIO_PORT=GPIOA
MotorControl.USART_SELECTION=USE_USART2
MotorControl.USART_SPEED=115200
MotorControl.USART_TX_GPIO_PIN=LL_GPIO_PIN_2
MotorControl.USART_TX_GPIO_PORT=GPIOA
MotorControl.USE_3OPAMPS=false
MotorControl.USE_INTERNAL_OPAMP=false
MotorControl.UV_VOLTAGE_PROT_ENABLING=true
MotorControl.V0_V=1.647
MotorControl.VARIANCE_THRESHOLD=0.1
MotorControl.VBUS_ADC=ADC1
MotorControl.VBUS_ADC_SAMPLING_TIME=47
MotorControl.VBUS_CHANNEL=ADC_CHANNEL_1
MotorControl.VBUS_GPIO_PIN=LL_GPIO_PIN_0
MotorControl.VBUS_GPIO_PORT=GPIOA
MotorControl.VBUS_PARTITIONING_FACTOR=0.0522
MotorControl.WB_to_Mx_template_version=21-02-18
MotorControl.WB_to_Mx_version=1.4.0
MotorControl.dV_dT=0.005
NVIC.ADC1_2_IRQn=true\:2\:0\:true\:true\:false\:3\:true\:true
NVIC.DMA1_Channel1_IRQn=true\:0\:0\:false\:false\:true\:false\:true
NVIC.DMA1_Channel2_IRQn=true\:0\:0\:false\:false\:true\:false\:true
NVIC.FDCAN1_IT0_IRQn=true\:6\:0\:true\:false\:true\:true\:true
NVIC.PriorityGroup=NVIC_PRIORITYGROUP_3
NVIC.SPI2_IRQn=true\:4\:0\:true\:false\:true\:true\:true
NVIC.TIM1_BRK_TIM15_IRQn=true\:4\:1\:true\:true\:false\:1\:true\:true
NVIC.TIM1_UP_TIM16_IRQn=true\:0\:0\:false\:true\:false\:2\:true\:true
NVIC.TIM4_IRQn=true\:3\:0\:false\:true\:false\:4\:true\:true
NVIC.TIM6_DAC_IRQn=true\:5\:0\:true\:false\:true\:true\:true
NVIC.TIM7_IRQn=true\:7\:0\:true\:false\:true\:true\:true
NVIC.USART2_IRQn=true\:3\:1\:true\:true\:false\:5\:true\:true
PA0.GPIO_Label=M1_BUS_VOLTAGE
PA0.Mode=IN1-Single-Ended
PA0.Signal=ADC1_IN1
PA1.GPIO_Label=M1_CURR_AMPL_U
PA1.Mode=IN2-Single-Ended
PA1.Signal=ADC1_IN2
PA10.GPIO_Label=M1_PWM_WH
PA10.GPIO_PuPd=GPIO_PULLDOWN
PA10.GPIO_Speed=GPIO_SPEED_FREQ_HIGH
PA10.Signal=S_TIM1_CH3
PA11.Mode=FDCAN_Activate
PA11.Signal=FDCAN1_RX
PA12.Mode=FDCAN_Activate
PA12.Signal=FDCAN1_TX
PA13.GPIO_Label=TMS
PA13.Mode=Serial_Wire
PA13.Signal=SYS_JTMS-SWDIO
PA14.GPIO_Label=TCK
PA14.Mode=Serial_Wire
PA14.Signal=SYS_JTCK-SWCLK
PA2.GPIO_Label=UART_TX
PA2.GPIO_Mode=GPIO_MODE_AF_PP
PA2.GPIO_PuPd=GPIO_NOPULL
PA2.GPIO_Speed=GPIO_SPEED_FREQ_LOW
PA2.Mode=Asynchronous
PA2.Signal=USART2_TX
PA3.GPIO_Label=UART_RX
PA3.GPIO_Mode=GPIO_MODE_AF_PP
PA3.GPIO_PuPd=GPIO_NOPULL
PA3.GPIO_Speed=GPIO_SPEED_FREQ_LOW
PA3.Mode=Asynchronous
PA3.Signal=USART2_RX
PA5.GPIO_Label=M1_TEMPERATURE
PA5.Mode=IN13-Single-Ended
PA5.Signal=ADC2_IN13
PA6.GPIO_Label=M1_CURR_AMPL_W
PA6.Mode=IN3-Single-Ended
PA6.Signal=ADC2_IN3
PA7.GPIO_Label=M1_PWM_UL
PA7.GPIO_PuPd=GPIO_PULLUP
PA7.GPIO_Speed=GPIO_SPEED_FREQ_HIGH
PA7.Mode=PWM Generation1 CH1 CH1N
PA7.Signal=TIM1_CH1N
PA8.GPIO_Label=M1_PWM_UH
PA8.GPIO_PuPd=GPIO_PULLDOWN
PA8.GPIO_Speed=GPIO_SPEED_FREQ_HIGH
PA8.Signal=S_TIM1_CH1
PA9.GPIO_Label=M1_PWM_VH
PA9.GPIO_PuPd=GPIO_PULLDOWN
PA9.GPIO_Speed=GPIO_SPEED_FREQ_HIGH
PA9.Signal=S_TIM1_CH2
PB0.GPIO_Label=M1_PWM_VL
PB0.GPIO_PuPd=GPIO_PULLUP
PB0.GPIO_Speed=GPIO_SPEED_FREQ_HIGH
PB0.Mode=PWM Generation2 CH2 CH2N
PB0.Signal=TIM1_CH2N
PB1.GPIO_Label=M1_PWM_WL
PB1.GPIO_PuPd=GPIO_PULLUP
PB1.GPIO_Speed=GPIO_SPEED_FREQ_HIGH
PB1.Mode=PWM Generation3 CH3 CH3N
PB1.Signal=TIM1_CH3N
PB11.GPIO_Label=M1_CURR_AMPL_V
PB11.Signal=SharedAnalog_PB11
PB13.Mode=Full_Duplex_Master
PB13.Signal=SPI2_SCK
PB14.Mode=Full_Duplex_Master
PB14.Signal=SPI2_MISO
PB15.Mode=Full_Duplex_Master
PB15.Signal=SPI2_MOSI
PB2.GPIO_Label=MA730_CS
PB2.Signal=GPIO_Output
PB4.GPIO_Label=DIP4
PB4.Signal=GPIO_Input
PB5.GPIO_Label=DIP3
PB5.Signal=GPIO_Input
PB6.GPIO_Label=M1_ENCODER_A
PB6.Signal=S_TIM4_CH1
PB7.GPIO_Label=M1_ENCODER_B
PB7.Signal=S_TIM4_CH2
PC13.GPIO_Label=DIP2
PC13.Signal=GPIO_Input
PC14-OSC32_IN.GPIO_Label=DIP1
PC14-OSC32_IN.Signal=GPIO_Input
PF0-OSC_IN.Mode=HSE-External-Oscillator
PF0-OSC_IN.Signal=RCC_OSC_IN
PF1-OSC_OUT.Mode=HSE-External-Oscillator
PF1-OSC_OUT.Signal=RCC_OSC_OUT
ProjectManager.HeapSize=0x200
ProjectManager.StackSize=0x400
ProjectManager.TargetToolchain=STM32CubeIDE
RCC.ADC12CLockSelection=RCC_ADC12CLKSOURCE_PLL
RCC.ADC12Freq_Value=42500000
RCC.AHBFreq_Value=170000000
RCC.APB1Freq_Value=170000000
RCC.APB1TimFreq_Value=170000000
RCC.APB2Freq_Value=170000000
RCC.APB2TimFreq_Value=170000000
RCC.CortexFreq_Value=170000000
RCC.EXTERNAL_CLOCK_VALUE=12288000
RCC.HCLKFreq_Value=170000000
RCC.HSE_VALUE=16000000
RCC.HSI48_VALUE=48000000
RCC.HSI_VALUE=16000000
RCC.LSE_VALUE=32768
RCC.PLLM=RCC_PLLM_DIV4
RCC.PLLN=85
RCC.PLLP=RCC_PLLP_DIV8
RCC.PLLSourceVirtual=RCC_PLLSOURCE_HSE
RCC.SYSCLKFreq_VALUE=170000000
RCC.SYSCLKSource=RCC_SYSCLKSOURCE_PLLCLK
RCC.USBFreq_Value=170000000
RCC.VCOOutputFreq_Value=340000000
SH.S_TIM1_CH1.0=TIM1_CH1,PWM Generation1 CH1 CH1N
SH.S_TIM1_CH2.0=TIM1_CH2,PWM Generation2 CH2 CH2N
SH.S_TIM1_CH3.0=TIM1_CH3,PWM Generation3 CH3 CH3N
SH.S_TIM4_CH1.0=TIM4_CH1,Encoder_Interface
SH.S_TIM4_CH2.0=TIM4_CH2,Encoder_Interface
SH.SharedAnalog_PB11.0=ADC1_IN14,IN14-Single-Ended
SH.SharedAnalog_PB11.1=ADC2_IN14,IN14-Single-Ended
SPI2.BaudRatePrescaler=SPI_BAUDRATEPRESCALER_16
SPI2.CalculateBaudRate=10.625 MBits/s
SPI2.DataSize=SPI_DATASIZE_16BIT
SPI2.Direction=SPI_DIRECTION_2LINES
SPI2.Mode=SPI_MODE_MASTER
SPI2.VirtualType=VM_MASTER
TIM1.AutoReloadPreload=TIM_AUTORELOAD_PRELOAD_DISABLE
TIM1.AutomaticOutput=TIM_AUTOMATICOUTPUT_DISABLE
TIM1.Break2Filter=0
TIM1.Break2Polarity=TIM_BREAK2POLARITY_HIGH
TIM1.Break2State=TIM_BREAK2_DISABLE
TIM1.BreakFilter=0
TIM1.BreakPolarity=TIM_BREAKPOLARITY_LOW
TIM1.BreakState=TIM_BREAK_DISABLE
TIM1.Channel=TIM_CHANNEL_4
TIM1.Channel-PWM\ Generation1\ CH1\ CH1N=TIM_CHANNEL_1
TIM1.Channel-PWM\ Generation2\ CH2\ CH2N=TIM_CHANNEL_2
TIM1.Channel-PWM\ Generation3\ CH3\ CH3N=TIM_CHANNEL_3
TIM1.Channel-PWM\ Generation4\ No\ Output=TIM_CHANNEL_4
TIM1.ClearInputSource=TIM_CLEARINPUTSOURCE_NONE
TIM1.ClockDivision=TIM_CLOCKDIVISION_DIV2
TIM1.CounterMode=TIM_COUNTERMODE_CENTERALIGNED1
TIM1.DeadTime=((DEAD_TIME_COUNTS) / 2)
TIM1.LockLevel=TIM_LOCKLEVEL_1
TIM1.OCFastMode_PWM=TIM_OCFAST_DISABLE
TIM1.OCIdleState_1=TIM_OCIDLESTATE_RESET
TIM1.OCIdleState_2=TIM_OCIDLESTATE_RESET
TIM1.OCIdleState_3=TIM_OCIDLESTATE_RESET
TIM1.OCIdleState_4=TIM_OCIDLESTATE_RESET
TIM1.OCIdleState_5=TIM_OCIDLESTATE_RESET
TIM1.OCIdleState_6=TIM_OCIDLESTATE_RESET
TIM1.OCMode_PWM-PWM\ Generation1\ CH1\ CH1N=TIM_OCMODE_PWM1
TIM1.OCMode_PWM-PWM\ Generation2\ CH2\ CH2N=TIM_OCMODE_PWM1
TIM1.OCMode_PWM-PWM\ Generation3\ CH3\ CH3N=TIM_OCMODE_PWM1
TIM1.OCMode_PWM-PWM\ Generation4\ No\ Output=TIM_OCMODE_PWM2
TIM1.OCNIdleState_1=TIM_OCNIDLESTATE_SET
TIM1.OCNIdleState_2=TIM_OCNIDLESTATE_SET
TIM1.OCNIdleState_3=TIM_OCNIDLESTATE_SET
TIM1.OCNPolarity_1=TIM_OCNPOLARITY_HIGH
TIM1.OCNPolarity_2=TIM_OCNPOLARITY_HIGH
TIM1.OCNPolarity_3=TIM_OCNPOLARITY_HIGH
TIM1.OCPolarity_1=TIM_OCPOLARITY_HIGH
TIM1.OCPolarity_2=TIM_OCPOLARITY_HIGH
TIM1.OCPolarity_3=TIM_OCPOLARITY_HIGH
TIM1.OCPolarity_4=TIM_OCPOLARITY_HIGH
TIM1.OCPolarity_5=TIM_OCPOLARITY_HIGH
TIM1.OCPolarity_6=TIM_OCPOLARITY_HIGH
TIM1.OffStateIDLEMode=TIM_OSSI_ENABLE
TIM1.OffStateRunMode=TIM_OSSR_ENABLE
TIM1.Period=((PWM_PERIOD_CYCLES) / 2)
TIM1.PeriodNoDither=((PWM_PERIOD_CYCLES) / 2)
TIM1.Prescaler=((TIM_CLOCK_DIVIDER) - 1)
TIM1.Pulse-PWM\ Generation1\ CH1=((PWM_PERIOD_CYCLES) / 4)
TIM1.Pulse-PWM\ Generation2\ CH2=((PWM_PERIOD_CYCLES) / 4)
TIM1.Pulse-PWM\ Generation3\ CH3=((PWM_PERIOD_CYCLES) / 4)
TIM1.Pulse-PWM\ Generation4\ No\ Output=(((PWM_PERIOD_CYCLES) / 2) - (HTMIN))
TIM1.Pulse-PWM\ Generation5\ No\ Output=(((PWM_PERIOD_CYCLES) / 2) + 1)
TIM1.Pulse-PWM\ Generation6\ No\ Output=(((PWM_PERIOD_CYCLES) / 2) + 1)
TIM1.RepetitionCounter=(REP_COUNTER)
TIM1.SourceBRK2DigInput=TIM_BREAKINPUTSOURCE_DISABLE
TIM1.TIM_MasterOutputTrigger=TIM_TRGO_OC4REF
TIM1.TIM_MasterOutputTrigger2=TIM_TRGO2_RESET
TIM1.TIM_MasterSlaveMode=TIM_MASTERSLAVEMODE_DISABLE
TIM1.TIM_SlaveMode=TIM_SLAVEMODE_TRIGGER
TIM4.EncoderMode=TIM_ENCODERMODE_TI12
TIM4.IC1Filter=M1_ENC_IC_FILTER
TIM4.IC1Polarity=TIM_ICPOLARITY_RISING
TIM4.IC2Filter=M1_ENC_IC_FILTER
TIM4.IC2Polarity=TIM_ICPOLARITY_RISING
TIM4.Period=M1_PULSE_NBR
TIM6.PeriodNoDither=16999
TIM7.PeriodNoDither=16999
TIM7.Prescaler=9
USART2.BaudRate=115200
USART2.VirtualMode-Asynchronous=VM_ASYNC
USART2.WordLength=WORDLENGTH_8B
VP_CORDIC_VS_CORDIC.Mode=CORDIC_Activate
VP_MotorControl_MC_ENABLED.Mode=Enabled
VP_SYS_VS_DBSignals.Mode=DisableDeadBatterySignals
VP_TIM1_VS_ClockSourceITR.Mode=TriggerSource_ITR1
VP_TIM1_VS_ControllerModeTrigger.Mode=Trigger Mode
VP_TIM1_VS_no_output4.Mode=PWM Generation4 No Output
VP_TIM6_VS_ClockSourceINT.Mode=Enable_Timer
VP_TIM7_VS_ClockSourceINT.Mode=Enable_Timer
board=custom

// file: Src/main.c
/* USER CODE BEGIN Header */
/**
  ******************************************************************************
  * @file           : main.c
  * @brief          : Main program body
  ******************************************************************************
  * @attention
  *
  * <h2><center>&copy; Copyright (c) 2022 STMicroelectronics.
  * All rights reserved.</center></h2>
  *
  * This software component is licensed by ST under Ultimate Liberty license
  * SLA0044, the "License"; You may not use this file except in compliance with
  * the License. You may obtain a copy of the License at:
  *                             www.st.com/SLA0044
  *
  ******************************************************************************
  */
/* USER CODE END Header */
#include "main.h"
#include "adc.h"
#include "cordic.h"
#include "dma.h"
#include "fdcan.h"
#include "spi.h"
#include "tim.h"
#include "usart.h"
#include "gpio.h"

/* USER CODE BEGIN PTD */
typedef struct {
//	uint16_t read_buffer;
	bool started;
	uint16_t angle;
	uint8_t z0;
	uint8_t z1;
	uint8_t bct;
	uint8_t ety;
	uint8_t etx;
	uint8_t ppt0;
	uint8_t ppt1;
	uint8_t ilip;
	uint8_t mglt;
	uint8_t mght;
	uint8_t rd;
	uint8_t mgh;
	uint8_t mgl;
} __attribute__ ((packed)) MA730_t;

typedef enum FSM_State {
	FSM_START = 0, /**< @brief Starting uC.*/
	FSM_INIT = 1,
	FSM_READY_TO_OPERATE = 2,
	FSM_OPERATION_ENABLE = 3, /**< @brief Enable power.*/

	FSM_CALIBRATION_PHASE_0 = 100,
	FSM_CALIBRATION_PHASE_1 = 101,
	FSM_CALIBRATION_PHASE_2 = 102,
	FSM_CALIBRATION_PHASE_3 = 103,
	FSM_CALIBRATION_PHASE_4 = 104,
	FSM_CALIBRATION_PHASE_5 = 105,
	FSM_CALIBRATION_PHASE_6 = 106,

	FSM_TRANSITION_START_TO_INIT = 10,
	FSM_TRANSITION_INIT_TO_READY_TO_OPERATE = 11,
	FSM_TRANSITION_READY_TO_OPERATE_TO_OPERATION_ENABLE = 12,
	FSM_TRANSITION_OPERATION_ENABLE_TO_READY_TO_OPERATE = 13,
	FSM_TRANSITION_FAULT_REACTION_ACTIVE_TO_FAULT = 14,
	FSM_TRANSITION_FAULT_TO_INIT = 15,

	FSM_TRANSITION_INIT_TO_CALIBRATION_PHASE_0 = 110,
	FSM_TRANSITION_CALIBRATION_PHASE_0_TO_CALIBRATION_PHASE_1 = 111,
	FSM_TRANSITION_CALIBRATION_PHASE_1_TO_CALIBRATION_PHASE_2 = 112,
	FSM_TRANSITION_CALIBRATION_PHASE_2_TO_CALIBRATION_PHASE_3 = 113,
	FSM_TRANSITION_CALIBRATION_PHASE_3_TO_CALIBRATION_PHASE_4 = 114,
	FSM_TRANSITION_CALIBRATION_PHASE_4_TO_CALIBRATION_PHASE_5 = 115,
	FSM_TRANSITION_CALIBRATION_PHASE_5_TO_CALIBRATION_PHASE_6 = 116,
	FSM_TRANSITION_CALIBRATION_PHASE_6_TO_INIT = 117,

	FSM_FAULT_REACTION_ACTIVE = 254,
	FSM_FAULT = 255
} FSM_State_t;

typedef enum Calibration_State {
	CALIBRATION_NOT_FINISHED = 0, /**< @brief Starting uC.*/
	CALIBRATION_TABLE_NOT_FILLED = 1, // No difference between hi and low value of the sector
	SECTORS_NARROW = 2, // No difference between hi and low value of the sector
	SECTORS_INTERCECTION = 3, // intersection of the sectors > 0
	SECTORS_NOT_SEPARETED = 3, // intersection of the sectors > 0
	CALIBRATION_TABLE_CONTAINS_ZEROES = 4,
	MISSED_CENTER_POSITION = 100,
	FLASH_DOESNT_WRITE_PROPERLY = 100,
	CALIBRATION_OK = 255
} Calibration_State_t;

typedef enum Joint_Calibratation_State {
	JOINT_NOT_CALIBRATED = 0, /**< @brief Starting uC.*/
	JOINT_CALIBRATED = 1
} Joint_Calibratation_State_t;

typedef enum Working_Mode {
	WORKING_MODE_NOT_SELECTED = 0, /**< @brief Starting uC.*/
	TORQUE_MODE,
	SPEED_MODE,
	POSITION_MODE
} Working_Mode_t;

typedef enum Motor {
	MOTOR_TYPE_NOT_SELECTED = 0, /**< @brief Starting uC.*/
	RI70,
	RI80
} Motor_t;

typedef struct {
	uint32_t main;
	uint32_t timer6;
	uint32_t timer7;
	uint32_t can_rx_counter;
	uint32_t can_tx_counter;
	uint32_t spi_rx_counter;
	uint32_t spi_tx_counter;
	uint32_t spi_txrx_counter;
} __attribute__ ((packed)) Counters_Handle_t;

typedef struct {
	uint8_t can_node_id;
	uint8_t gear_ratio;
	uint8_t pole_pairs;
	Motor_t motor_type;
//	uint16_t encoder_resolution;

	bool dip1;
	bool dip2;
	bool dip3;
	bool dip4;
	bool ma730_enabled;
//	bool canbus_enabled;
//	bool canbus_watchdog_enabled;
	bool working_area_constrain_enabled; /**< @brief settings to enable/disable constrain */

	Joint_Calibratation_State_t calibration_state;

	uint16_t maximum_electrical_rotations;
	uint16_t reachable_electrical_rotations;

	uint16_t number_of_sectors;
	int16_t  zero_electric_position;
	uint16_t zero_electric_rotation;
	float joint_working_area;
	uint16_t calibration_sector_size; // in electrical rotations
	uint16_t calibration_table_size;
	uint16_t calibration_table_1[512];
	uint16_t calibration_table_2[512];

} __attribute__ ((packed)) Joint_Configuration_Handle_t;

typedef struct {
	Working_Mode_t working_mode;
	float joint_torque;				// Nm
	float motor_torque;				// Nm
	float joint_speed;				// rads
	float motor_speed;				// rads
	float joint_position;			// rad
	float motor_position;			// rad
	int16_t _motor_torque;			//
	int16_t _motor_speed;			//
	int32_t _motor_position;		//
} __attribute__ ((packed)) App_Command_Handle_t;

typedef enum Joint_Position_State {
	POSITION_UNDER_WORKING_AREA = -1,
	POSITION_IN_WORKING_AREA = 0, /**< @brief Starting uC.*/
	POSITION_OVER_WORKING_AREA = 1
} Joint_Position_State_t;

typedef enum Encoder_Position_State {
	POSITION_UNKNOWN = 0, /**< @brief Starting uC.*/
	POSITION_APROXIMATED = 1,
	POSITION_ACCURATE = 2,
	POSITION_ESTIMATION_FAILED = 255
} Encoder_Position_State_t;

typedef struct {
	Joint_Position_State_t current_joint_position;
	Encoder_Position_State_t encoder_position_state;

	float f_current_encoder_position_offset;	// rad

	float f_current_motor_position; 			// rad
	float f_current_joint_position; 			// rad
	float f_current_motor_speed; 				// rad/s
	float f_current_joint_speed; 				// rad/s
	float f_current_motor_torque; 				// Nm
	float f_current_joint_torque; 				// Nm
	float f_current_motor_temperature;			// C
	float f_current_voltage;					// V

	int16_t mc_current_motor_torque;
	int16_t mc_current_motor_speed;
	int32_t mc_current_motor_rotation;
	int32_t mc_current_motor_position_multiturn;
	uint16_t mc_current_motor_position;
	uint16_t mc_previous_motor_position;
	int32_t mc_current_electric_rotation;
	int16_t mc_current_electric_position;
	int16_t mc_previous_electric_position;

	uint8_t errors;
	uint8_t warnings;

//	PosCtrlStatus_t mc_position_control_status;
//	AlignStatus_t mc_encoder_align_status;
	State_t stm_state_motor;
	uint8_t mc_current_faults_motor;
	uint8_t mc_occured_faults_motor;

	int16_t _current_torque_data[CURRENT_TORQUE_DATA_SIZE];
	uint8_t _current_torque_index;

	int16_t _current_speed_data[CURRENT_SPEED_DATA_SIZE];
	uint8_t _current_speed_index;
} __attribute__ ((packed)) Joint_Status_Handle_t;

typedef struct {
	FSM_State_t state;
	bool state_is_running;
	bool transition_is_running;
} __attribute__ ((packed)) FSMStatus_t;
/* USER CODE END PTD */

/* USER CODE BEGIN PD */
#define GEAR_RATIO							(uint16_t) 121
#define SECTOR_SIZE							(uint16_t) 5
#define POLE_PAIRS							(uint16_t) 14
#define JOINT_SPEED_LIMIT					(float) 1.0
//#define KT									(float) 0.1118
//#define JOINT_TYPE							JOINT_MEDIUM
#define CALIBRATION_TORQUE_LIMIT			2000
#define CALIBRATION_ZERO_POSITION_OFFSET	10

/* USER CODE END PD */

/* USER CODE BEGIN PM */
#define NOP asm("NOP")
/* USER CODE END PM */

/* USER CODE BEGIN PV */
FDCAN_RxHeaderTypeDef can_rx_header; // CAN Bus Transmit Header
FDCAN_TxHeaderTypeDef can_tx_header; // CAN Bus Transmit Header
uint8_t can_rx_data[24] = {0,0,0,0,0,0,0,0,0,0,0,0,0,0,0,0,0,0,0,0,0,0,0,0};  //CAN Bus Receive Buffer
uint8_t can_tx_data[24] = {0,0,0,0,0,0,0,0,0,0,0,0,0,0,0,0,0,0,0,0,0,0,0,0};  //CAN Bus Send Buffer

uint16_t g_spi_rx_data    = 0x0000 ;
uint16_t g_spi_tx_data    = 0x0000 ;

// FLASH
uint32_t g_flash_address_configuration 		= 0x08018000; // FIXME zmienic na 0x08018000
uint32_t g_flash_address_calibration_table 	= 0x08018100;
uint16_t g_calibration_config[16] = {0, 0, 0, 0, 0, 0, 0, 0, 0, 0, 0, 0, 0, 0, 0, 0};
uint32_t g_data[2] = {0, 0};

Counters_Handle_t volatile g_counters =
{
	.main = 0,
	.timer6 = 0,
	.timer7 = 0,
	.spi_rx_counter = 0,
	.spi_tx_counter = 0,
	.spi_txrx_counter = 0,

};

App_Command_Handle_t g_app_command =
{
	.working_mode = TORQUE_MODE,
	.motor_torque = 0.0,
};

Joint_Configuration_Handle_t g_joint_configuration =
{
	.ma730_enabled = false,
	.working_area_constrain_enabled = false,
	.motor_type = RI70,
	.can_node_id = 0x00,
	.gear_ratio = 121
};

Joint_Status_Handle_t g_joint_status =
{
	.mc_current_motor_position = 0
};

volatile MA730_t 	g_ma730 =
{
	.started = false,
};

volatile FSMStatus_t 	g_fsm_status =
{
	.state = FSM_START,
	.state_is_running = false,
	.transition_is_running = false,
};

// Calibration variables
volatile Calibration_State_t g_calibration_state = CALIBRATION_NOT_FINISHED;

volatile uint16_t g_calibration_speed = 10; // speed of configuration rotations
volatile uint16_t g_calibration_torque_limit = CALIBRATION_TORQUE_LIMIT;

volatile int32_t g_min_encoder_position = 0;
volatile int32_t g_max_encoder_position = 0;
volatile int32_t g_center_encoder_position = 0;
volatile int16_t g_max_electric_rotation_cw  = 0;
volatile int16_t g_max_electric_rotation_ccw = 0;
volatile uint16_t g_calibration_data_1_errors = 0;
volatile uint16_t g_calibration_data_2_errors = 0;

int16_t g_current_sector_number = -1;
int16_t g_previous_sector_number = -1;
int16_t g_current_estimated_electric_rotation = -1;
/* USER CODE END PV */

void SystemClock_Config(void);
static void MX_NVIC_Init(void);
/* USER CODE BEGIN PFP */
FSM_State_t FSM_Get_State(void);
bool FSM_Set_State(FSM_State_t new_state);
bool FSM_Activate_State(FSM_State_t new_state);
bool FSM_Activate_Transition(FSM_State_t new_transition);
/* USER CODE END PFP */

int main(void)
{

  /* MCU Configuration--------------------------------------------------------*/

  /* Reset of all peripherals, Initializes the Flash interface and the Systick. */
  HAL_Init();

  /* Configure the system clock */
  SystemClock_Config();

  /* Initialize all configured peripherals */
  MX_GPIO_Init();
  MX_ADC1_Init();
  MX_ADC2_Init();
  MX_CORDIC_Init();
  MX_TIM1_Init();
  MX_TIM4_Init();
  MX_USART2_UART_Init();
  MX_DMA_Init();
  MX_SPI2_Init();
  MX_MotorControl_Init();
  MX_FDCAN1_Init();
  MX_TIM6_Init();
  MX_TIM7_Init();

  /* Initialize interrupts */
  MX_NVIC_Init();
  /* USER CODE BEGIN 2 */

  // TIMERS
  HAL_TIM_Base_Start_IT(&htim6); 	// Enable 10 kHz timer for fast calculation
  HAL_TIM_Base_Start_IT(&htim7);  	// Enable  1 kHz timer for FSM

  /* USER CODE END 2 */

  /* Infinite loop */
  while (1)
  {

    /* USER CODE BEGIN 3 */
	  g_counters.main++;
  }
  /* USER CODE END 3 */
}

void SystemClock_Config(void)
{
  RCC_OscInitTypeDef RCC_OscInitStruct = {0};
  RCC_ClkInitTypeDef RCC_ClkInitStruct = {0};
  RCC_PeriphCLKInitTypeDef PeriphClkInit = {0};

  /** Configure the main internal regulator output voltage
  */
  HAL_PWREx_ControlVoltageScaling(PWR_REGULATOR_VOLTAGE_SCALE1_BOOST);
  /** Initializes the RCC Oscillators according to the specified parameters
  * in the RCC_OscInitTypeDef structure.
  */
  RCC_OscInitStruct.OscillatorType = RCC_OSCILLATORTYPE_HSE;
  RCC_OscInitStruct.HSEState = RCC_HSE_ON;
  RCC_OscInitStruct.PLL.PLLState = RCC_PLL_ON;
  RCC_OscInitStruct.PLL.PLLSource = RCC_PLLSOURCE_HSE;
  RCC_OscInitStruct.PLL.PLLM = RCC_PLLM_DIV4;
  RCC_OscInitStruct.PLL.PLLN = 85;
  RCC_OscInitStruct.PLL.PLLP = RCC_PLLP_DIV8;
  RCC_OscInitStruct.PLL.PLLQ = RCC_PLLQ_DIV2;
  RCC_OscInitStruct.PLL.PLLR = RCC_PLLR_DIV2;
  if (HAL_RCC_OscConfig(&RCC_OscInitStruct) != HAL_OK)
  {
    Error_Handler();
  }
  /** Initializes the CPU, AHB and APB buses clocks
  */
  RCC_ClkInitStruct.ClockType = RCC_CLOCKTYPE_HCLK|RCC_CLOCKTYPE_SYSCLK
                              |RCC_CLOCKTYPE_PCLK1|RCC_CLOCKTYPE_PCLK2;
  RCC_ClkInitStruct.SYSCLKSource = RCC_SYSCLKSOURCE_PLLCLK;
  RCC_ClkInitStruct.AHBCLKDivider = RCC_SYSCLK_DIV1;
  RCC_ClkInitStruct.APB1CLKDivider = RCC_HCLK_DIV1;
  RCC_ClkInitStruct.APB2CLKDivider = RCC_HCLK_DIV1;

  if (HAL_RCC_ClockConfig(&RCC_ClkInitStruct, FLASH_LATENCY_4) != HAL_OK)
  {
    Error_Handler();
  }
  /** Initializes the peripherals clocks
  */
  PeriphClkInit.PeriphClockSelection = RCC_PERIPHCLK_USART2|RCC_PERIPHCLK_ADC12
                              |RCC_PERIPHCLK_FDCAN;
  PeriphClkInit.Usart2ClockSelection = RCC_USART2CLKSOURCE_PCLK1;
  PeriphClkInit.FdcanClockSelection = RCC_FDCANCLKSOURCE_PCLK1;
  PeriphClkInit.Adc12ClockSelection = RCC_ADC12CLKSOURCE_PLL;
  if (HAL_RCCEx_PeriphCLKConfig(&PeriphClkInit) != HAL_OK)
  {
    Error_Handler();
  }
}

/**
  * @brief NVIC Configuration.
  * @retval None
  */
static void MX_NVIC_Init(void)
{
  /* TIM1_BRK_TIM15_IRQn interrupt configuration */
  HAL_NVIC_SetPriority(TIM1_BRK_TIM15_IRQn, 4, 1);
  HAL_NVIC_EnableIRQ(TIM1_BRK_TIM15_IRQn);
  /* TIM1_UP_TIM16_IRQn interrupt configuration */
  HAL_NVIC_SetPriority(TIM1_UP_TIM16_IRQn, 0, 0);
  HAL_NVIC_EnableIRQ(TIM1_UP_TIM16_IRQn);
  /* ADC1_2_IRQn interrupt configuration */
  HAL_NVIC_SetPriority(ADC1_2_IRQn, 2, 0);
  HAL_NVIC_EnableIRQ(ADC1_2_IRQn);
  /* TIM4_IRQn interrupt configuration */
  HAL_NVIC_SetPriority(TIM4_IRQn, 3, 0);
  HAL_NVIC_EnableIRQ(TIM4_IRQn);
  /* USART2_IRQn interrupt configuration */
  HAL_NVIC_SetPriority(USART2_IRQn, 3, 1);
  HAL_NVIC_EnableIRQ(USART2_IRQn);
}

/* USER CODE BEGIN 4 */
void motor_start(Working_Mode_t mode, int16_t goal)
{

	g_app_command.working_mode = mode;

	switch (g_app_command.working_mode)
	{
		case TORQUE_MODE:
		{
			g_app_command._motor_torque = goal;
			MC_ProgramTorqueRampMotor1(g_app_command._motor_torque, 0);
			MC_StartMotor1();
			break;
		}

		case SPEED_MODE:
		{
			g_app_command._motor_speed = goal;
			MC_ProgramSpeedRampMotor1(g_app_command._motor_speed, 0);
			MC_StartMotor1();
			break;
		}

//			case POSITION_MODE:
//			{
//				MC_ProgramPositionCommandMotor1(g_app_command.motor_position, 0.1);
////				MC_ProgramSpeedRampMotor1(g_app_command._motor_position, 0);
////				MC_StartMotor1();
////				MC_ProgramPositionCommandMotor1(g_app_command.joint_position, 0.1);
////				MC_StartMotor1();
////				HAL_Delay(2000);
//				break;
//			}

		default:
		{
			MC_StopMotor1();
		}
	}

//	g_motor_command.goal = goal;
////	g_motor_command.last_goal = goal;
//	g_motor_command.mode = mode;
//
//	switch (mode)
//	{
//		case TORQUE:
//		{
//			g_motor_command.state = MOTOR_STARTED_IN_TORQUE_MODE;
//			MC_ProgramTorqueRampMotor1(g_motor_command.goal, 0);
//			break;
//		}
//
//		case SPEED:
//		{
//			g_motor_command.state = MOTOR_STARTED_IN_SPEED_MODE;
//			MC_ProgramSpeedRampMotor1(g_motor_command.goal, 0);
//			break;
//		}
//
//		default:
//		{
//			g_motor_command.goal = 0;
////			g_motor_command.last_goal = 0;
//			return;
//		}
//	}
//
//	MC_StartMotor1();
}

void motor_stop()
{

	// clear torque readings
	for (int i = 0; i < CURRENT_TORQUE_DATA_SIZE; i++)
	{
		g_joint_status._current_torque_data[i] = 0;
	}

	g_app_command._motor_torque = 0;
	g_app_command.motor_torque = 0;
	g_app_command.joint_torque = 0;

	g_app_command._motor_speed = 0;
	g_app_command.motor_speed = 0;
	g_app_command.joint_speed = 0;

	MC_StopMotor1();
}

bool motor_reach_torque_limit()
{
	if (g_joint_status.mc_current_motor_torque > g_calibration_torque_limit && g_joint_status.stm_state_motor == RUN) return true;

	return false;
}

bool motor_in_position(volatile int32_t position)
{
	if (abs(g_joint_status.mc_current_motor_position_multiturn - position) < CALIBRATION_ZERO_POSITION_OFFSET) return true;

	return false;
}

bool check_calibration_data_cw(int16_t size) {
	g_calibration_data_1_errors = 0;

	for (int i = 0; i < size; i++) {
//		if (calibration_data_1[i] == 0) g_calibration_data_1_errors++;
		if (g_joint_configuration.calibration_table_1[i] == 0) g_calibration_data_1_errors++;

	}

	if (g_calibration_data_1_errors > 0) return false;

	return true;
}

bool check_calibration_data_ccw(int16_t size) {
	g_calibration_data_2_errors = 0;

	for (int i = 0; i < size; i++) {
//		if (calibration_data_2[i] == 0) g_calibration_data_2_errors++;
		if (g_joint_configuration.calibration_table_2[i] == 0) g_calibration_data_2_errors++;
	}

	if (g_calibration_data_2_errors > 0) return false;

	return true;
}

// l - poczatek, r - koniec, x - szukane, arr - lista
// l - lewy sektor, r - prawy sektor, x - ma730, o - offset
#pragma GCC push_options
#pragma GCC optimize ("O0")
int16_t get_sector_number_from_calibration(uint16_t left_index, uint16_t right_index, uint16_t ma730_value, uint16_t offset)
{
    if (right_index >= left_index) {
    	int16_t mid = left_index + (right_index - left_index) / 2; // srodek

    	uint32_t mid_left_value  = g_joint_configuration.calibration_table_1[mid];    // wartosc lewego brzegu sektora
    	uint32_t mid_right_value = g_joint_configuration.calibration_table_2[mid];    // wartosc prawego brzegu sektora
    	uint32_t searched_value  = ma730_value; // wartosc szukana

    	// Przesuniecie wartosci o offset, by funkcja byla w całej długości ciągła
    	if (mid_left_value <= offset)
    	{
    		mid_left_value += 16384;
    	}

    	if (mid_right_value <= offset)
    	{
    		mid_right_value += 16384;
    	}

    	if (searched_value <= offset)
    	{
    		searched_value += 16384;
    	}

        // If the element is present at the middle
        // itself
		if (searched_value >= mid_left_value && searched_value <= mid_right_value ) // czy jest w sektorze srodkowym - jezeli tak, to koniec
		{
			return mid; // dobry sektor
		}

    	if (left_index == right_index) {
    		return -1;
    	}

        // If element is smaller than mid, then
        // it can only be present in left subarray
        if (mid_left_value > searched_value) // element jest mniejszsy niz srodkowy
        {
			uint16_t index = get_sector_number_from_calibration(left_index, mid - 1, ma730_value, offset); // szukaj z lewej strony
			return index;
        }

        // Else the element can only be present
        // in right subarray
        return get_sector_number_from_calibration(mid + 1, right_index, ma730_value, offset);  // szukaj z prawej strony
    }

    // We reach here when element is not
    // present in array
    return -1; // element poza sektorami
}
#pragma GCC pop_options
void Flash_Read_Data(uint32_t StartPageAddress, uint32_t *RxBuf, uint16_t numberofwords)
{
	while (1)
	{
		*RxBuf = *(__IO uint32_t *)StartPageAddress;
		StartPageAddress += 4;
		RxBuf++;
		if (!(numberofwords--)) break;
	}
}

void Read_MC_Encoder_10kHz() // odczyt danych enkdera i sprawdzanie obrotow
{
	// CALCULATE CHANGE ELECTRIC ROTATION
	g_joint_status.mc_previous_electric_position = g_joint_status.mc_current_electric_position; // store old position
	g_joint_status.mc_current_electric_position = ENCODER_M1._Super.hElAngle;

	if (g_joint_status.mc_previous_electric_position > 28000 && g_joint_status.mc_current_electric_position < - 28000)
	{
		g_joint_status.mc_current_electric_rotation++;
	}
	if (g_joint_status.mc_current_electric_position > 28000  && g_joint_status.mc_previous_electric_position < - 28000)
	{
		g_joint_status.mc_current_electric_rotation--;
	}
}

void Read_MC_Encoder_1kHz() // odczyt danych enkdera i sprawdzanie obrotow
{
	// READ POSITION
	g_joint_status.mc_previous_motor_position = g_joint_status.mc_current_motor_position; // store old position
	g_joint_status.mc_current_motor_position = ENCODER_M1.PreviousCapture; // 0 ... 14336 - 1 mechanical motor rotation

	if (g_joint_status.mc_previous_motor_position > ENCODER_M1.PulseNumber - ENCODER_M1.PulseNumber / 4 && g_joint_status.mc_current_motor_position  < ENCODER_M1.PulseNumber / 4)
	{
		g_joint_status.mc_current_motor_rotation++;
	}
	if (g_joint_status.mc_current_motor_position  > ENCODER_M1.PulseNumber - ENCODER_M1.PulseNumber / 4 && g_joint_status.mc_previous_motor_position < ENCODER_M1.PulseNumber / 4)
	{
		g_joint_status.mc_current_motor_rotation--;
	}

	g_joint_status.mc_current_motor_position_multiturn = g_joint_status.mc_current_motor_position + g_joint_status.mc_current_motor_rotation * ENCODER_M1.PulseNumber;

	// READ SPEED
	if (g_joint_status.mc_previous_motor_position - g_joint_status.mc_current_motor_position > ENCODER_M1.PulseNumber / 2)
	{
		g_joint_status._current_speed_data[g_joint_status._current_speed_index++] = g_joint_status.mc_previous_motor_position - g_joint_status.mc_current_motor_position - ENCODER_M1.PulseNumber;
	}
	else if (g_joint_status.mc_previous_motor_position - g_joint_status.mc_current_motor_position < -1 * ENCODER_M1.PulseNumber / 2)
	{
		g_joint_status._current_speed_data[g_joint_status._current_speed_index++] = g_joint_status.mc_previous_motor_position - g_joint_status.mc_current_motor_position + ENCODER_M1.PulseNumber;
	}
	else
	{
		g_joint_status._current_speed_data[g_joint_status._current_speed_index++] = g_joint_status.mc_previous_motor_position - g_joint_status.mc_current_motor_position;
	}
	g_joint_status._current_speed_index %= CURRENT_SPEED_DATA_SIZE;

}

void Read_MC_Torque() // odczyt surowych danych torque
{
	// READ TORQUE
	g_joint_status._current_torque_data[g_joint_status._current_torque_index++] = MC_GetPhaseCurrentAmplitudeMotor1();
	g_joint_status._current_torque_index %= CURRENT_TORQUE_DATA_SIZE;
}

void Read_MC_State()
{
	g_joint_status.stm_state_motor 				= MC_GetSTMStateMotor1();
	g_joint_status.mc_current_faults_motor 		= (uint8_t) MC_GetCurrentFaultsMotor1();
	g_joint_status.mc_occured_faults_motor 		= (uint8_t) MC_GetOccurredFaultsMotor1();
//	g_joint_status.mc_encoder_align_status  	= MC_GetAlignmentStatusMotor1();
//	g_joint_status.mc_position_control_status 	= MC_GetControlPositionStatusMotor1();
	g_joint_status.f_current_motor_temperature 	= (uint8_t) NTC_GetAvTemp_C(&TempSensorParamsM1);
}

void Update_Data_From_MC()
{
	// POSITION
	g_joint_status.f_current_motor_position = ((double) g_joint_status.mc_current_motor_position_multiturn / ENCODER_M1.PulseNumber) * M_TWOPI;
	g_joint_status.f_current_joint_position = (double) g_joint_status.f_current_motor_position / g_joint_configuration.gear_ratio + g_joint_status.f_current_encoder_position_offset;

	// SPEED
	float temp_speed = 0;
	for (int i = 0; i < CURRENT_SPEED_DATA_SIZE; i++)
	{
		temp_speed += (float) g_joint_status._current_speed_data[i];
	}

	g_joint_status.mc_current_motor_speed	= temp_speed / CURRENT_SPEED_DATA_SIZE; // impulses per 1ms
	g_joint_status.f_current_motor_speed 	= ((float) temp_speed / CURRENT_SPEED_DATA_SIZE * 1000.0 / ENCODER_M1.PulseNumber) * M_TWOPI;
	g_joint_status.f_current_joint_speed 	= g_joint_status.f_current_motor_speed / g_joint_configuration.gear_ratio;

	// TORQUE
	// recalculate_torques
	float temp_torque = 0;
	for (int i = 0; i < CURRENT_TORQUE_DATA_SIZE; i++)
	{
		temp_torque += (float) g_joint_status._current_torque_data[i];
	}

	g_joint_status.mc_current_motor_torque			= temp_torque / CURRENT_TORQUE_DATA_SIZE;
	g_joint_status.f_current_motor_torque			= (((float) (temp_torque / CURRENT_TORQUE_DATA_SIZE)) / INT16_MAX) * MAX_READABLE_CURRENT * KT;
	g_joint_status.f_current_joint_torque			= g_joint_status.f_current_motor_torque * g_joint_configuration.gear_ratio;

}

void CheckErrorsAndWarnings()
{
	bool error = false;

	// MOTOR CONTROL ERROR REACTION
	if ((g_joint_status.mc_current_faults_motor > 0 || g_joint_status.mc_occured_faults_motor > 0) && FSM_Get_State() != FSM_TRANSITION_FAULT_TO_INIT) {
		g_joint_status.errors =  g_joint_status.errors | JOINT_MC_FAILED;
		error = true;
	}
	else
	{
		g_joint_status.errors = g_joint_status.errors & (0xFF ^ JOINT_MC_FAILED);
	}

	// OVERSPEED ERROR REACTION
	if ((fabs(g_joint_status.f_current_joint_speed) > JOINT_SPEED_LIMIT) && FSM_Get_State() != FSM_TRANSITION_FAULT_TO_INIT) {
		g_joint_status.errors =  g_joint_status.errors | JOINT_JOINT_SPEED_TO_HIGH;
		error = true;
//	}
//	else
//	{
//		g_joint_status.errors = g_joint_status.errors & (0xFF ^ JOINT_JOINT_SPEED_TO_HIGH);
	}

	// WARNINGS:
	// WORKING AREA
	if (g_joint_status.f_current_joint_position < -1 * g_joint_configuration.joint_working_area && g_joint_configuration.working_area_constrain_enabled)
	{
		g_joint_status.current_joint_position = POSITION_UNDER_WORKING_AREA;
		g_joint_status.warnings = g_joint_status.warnings | JOINT_OUTSIDE_WORKING_AREA;
	}
	else if(g_joint_status.f_current_joint_position > g_joint_configuration.joint_working_area && g_joint_configuration.working_area_constrain_enabled)
	{
		g_joint_status.current_joint_position = POSITION_OVER_WORKING_AREA;
		g_joint_status.warnings = g_joint_status.warnings | JOINT_OUTSIDE_WORKING_AREA;
	}
	else
	{
		g_joint_status.current_joint_position = POSITION_IN_WORKING_AREA;
		g_joint_status.warnings = g_joint_status.warnings & (0xFF ^ JOINT_OUTSIDE_WORKING_AREA);
	}

	// ENCODER_NOT_ACCURATE
	if (g_joint_status.encoder_position_state != POSITION_ACCURATE)
	{
		g_joint_status.warnings = g_joint_status.warnings | JOINT_POSITION_NOT_ACCURATE;

	}
	else
	{
		g_joint_status.warnings = g_joint_status.warnings & (0xFF ^ JOINT_POSITION_NOT_ACCURATE);
	}

	if (error == true && FSM_Get_State() != FSM_FAULT && FSM_Get_State() != FSM_FAULT_REACTION_ACTIVE && FSM_Get_State() != FSM_TRANSITION_FAULT_REACTION_ACTIVE_TO_FAULT)
	{
		FSM_Activate_State(FSM_FAULT_REACTION_ACTIVE);
	}

}

void FSM_Action()
{
}

void HAL_SPI_TxRxCpltCallback(SPI_HandleTypeDef * hspi)
{
	HAL_GPIO_WritePin(MA730_CS_GPIO_Port, MA730_CS_Pin, GPIO_PIN_SET);

    // TX-RX Done .. Do Something ...
	g_counters.spi_txrx_counter++;

	g_ma730.angle = (g_spi_rx_data >> 2) & 0b0011111111111111;

	if (g_ma730.started)
	{
		HAL_GPIO_WritePin(MA730_CS_GPIO_Port, MA730_CS_Pin, GPIO_PIN_RESET);

		if (HAL_SPI_TransmitReceive_IT(&hspi2, (uint8_t * ) &g_spi_tx_data, (uint8_t * ) &g_spi_rx_data, 1) != HAL_OK)
		{
			Error_Handler();
		}
	}

}

void HAL_TIM_PeriodElapsedCallback(TIM_HandleTypeDef *htim)
{
	if(htim->Instance == TIM6) 	// 10kHz (5,0) - fast recalculation
	{
		g_counters.timer6++;
		Read_MC_Encoder_10kHz();
		Read_MC_Torque();
		Read_MC_State();
	}

	if(htim->Instance == TIM7) 	// 1kHz - FSM_Tasks
	{
		Read_MC_Encoder_1kHz();
		CheckErrorsAndWarnings();
		Update_Data_From_MC();

		// Estimate joint position from absolute encoder
		if (g_joint_configuration.ma730_enabled == true && g_joint_configuration.calibration_state == JOINT_CALIBRATED && g_ma730.started == true)
		{
			// JOINT POSITION ESTIMATION
			switch (g_joint_status.encoder_position_state)
			{
				case POSITION_ESTIMATION_FAILED:
				{
					// RAISE ERROR
					break;
				}

				case POSITION_ACCURATE:
				{
					break;
				}

				case POSITION_APROXIMATED:
				{
					g_current_sector_number = get_sector_number_from_calibration(0, g_joint_configuration.number_of_sectors - 1, g_ma730.angle, g_joint_configuration.calibration_table_1[0]);

					// If motor running and sector is change update
					if (g_current_sector_number != g_previous_sector_number && g_previous_sector_number != -1 && g_current_sector_number != -1) // pass 1 time, to load previous and current
					{
						float electric_rotation_width = M_TWOPI / (g_joint_configuration.pole_pairs * g_joint_configuration.gear_ratio);
						uint16_t l_current_electric_rotation;

						if (g_current_sector_number - g_previous_sector_number > 0)
						{ // rotation in CCW direction => "+"
							l_current_electric_rotation = (g_current_sector_number) * g_joint_configuration.calibration_sector_size;
						}
						else
						{ // rotation in CW direction ==> "-"
							l_current_electric_rotation = (g_current_sector_number + 1) * g_joint_configuration.calibration_sector_size - 1;
						}
						int32_t l_diff_electric_position = g_joint_configuration.zero_electric_position - g_joint_status.mc_current_motor_position_multiturn;
						g_joint_status.mc_current_electric_rotation = l_current_electric_rotation;

						float l_electric_offset_to_zero_in_rad   = -1 * ((g_joint_configuration.zero_electric_rotation - l_current_electric_rotation) + ((float) l_diff_electric_position / 65536) - 1.0) * electric_rotation_width;
						float l_encoder_offset_to_current_in_rad = -1 * ((float) g_joint_status.mc_current_motor_position_multiturn / (ENCODER_M1.PulseNumber / g_joint_configuration.pole_pairs)) * electric_rotation_width;

//							g_motor_status.current_encoder_position_offset_in_rad = -1 * ((g_joint_configuration.zero_electric_rotation - l_current_electric_rotation) + ((float) l_diff_electric_position / 65536) - 1.0) * electric_rotation_width;
						g_joint_status.f_current_encoder_position_offset = l_electric_offset_to_zero_in_rad + l_encoder_offset_to_current_in_rad;

						g_joint_status.encoder_position_state = POSITION_ACCURATE;
					}

					if (g_current_sector_number != -1)
					{
						g_previous_sector_number = g_current_sector_number;
					}

					break;
				}

				case POSITION_UNKNOWN:
				{
					g_current_sector_number = get_sector_number_from_calibration(0, g_joint_configuration.number_of_sectors - 1, g_ma730.angle, g_joint_configuration.calibration_table_1[0]);
					if (g_current_sector_number != -1)
					{
						float electric_rotation_width = M_TWOPI / (g_joint_configuration.pole_pairs * g_joint_configuration.gear_ratio);

						g_current_estimated_electric_rotation = g_current_sector_number *  g_joint_configuration.calibration_sector_size; // center current sector

						g_joint_status.f_current_encoder_position_offset = -1 * (g_joint_configuration.zero_electric_rotation - g_current_estimated_electric_rotation) * electric_rotation_width;

						// calculate encoder positioon offset
						g_joint_status.encoder_position_state = POSITION_APROXIMATED;
					}
					break;
				}
			}

		}
		// FSM
		switch (FSM_Get_State()) {

			case FSM_CALIBRATION_PHASE_0:
			{
				g_joint_configuration.calibration_state = JOINT_NOT_CALIBRATED;

				g_joint_configuration.calibration_sector_size = SECTOR_SIZE;
				g_joint_configuration.pole_pairs = POLE_PAIRS;
				g_joint_configuration.gear_ratio = GEAR_RATIO;
				g_joint_configuration.maximum_electrical_rotations = g_joint_configuration.gear_ratio * g_joint_configuration.pole_pairs;
				g_joint_configuration.calibration_table_size = (uint16_t) (g_joint_configuration.maximum_electrical_rotations / g_joint_configuration.calibration_sector_size);

				g_joint_configuration.reachable_electrical_rotations = 0;
				g_joint_configuration.number_of_sectors = 0;
				g_joint_configuration.zero_electric_position = 0;
				g_joint_configuration.zero_electric_rotation = 0;
				for (int i = 0; i < g_joint_configuration.calibration_table_size; i++)
				{
					g_joint_configuration.calibration_table_1[i] = 0;
					g_joint_configuration.calibration_table_2[i] = 0;
				}

				g_fsm_status.state = FSM_CALIBRATION_PHASE_1;
				break;
			}

			case FSM_CALIBRATION_PHASE_1:
			{

				if (motor_reach_torque_limit()) // REACH MINIMUM EDGE
				{
					motor_stop();
					g_joint_status.mc_current_electric_rotation = 0; // zeroing electric rotation counter
					g_min_encoder_position = g_joint_status.mc_current_motor_position_multiturn; // encoder value

					g_fsm_status.state = FSM_CALIBRATION_PHASE_2;

				}
				else
				{
					motor_start(SPEED_MODE, -1 * g_calibration_speed);
				}

				break;
			}

			case FSM_CALIBRATION_PHASE_2:
			{
				if (g_joint_status.mc_current_electric_rotation % g_joint_configuration.calibration_sector_size == (0) &&
						g_joint_configuration.calibration_table_1[g_joint_status.mc_current_electric_rotation / g_joint_configuration.calibration_sector_size] == 0)
				{
					g_joint_configuration.calibration_table_1[g_joint_status.mc_current_electric_rotation / g_joint_configuration.calibration_sector_size] = g_ma730.angle;
				}

				if (motor_reach_torque_limit()) // REACH MAXIMUM EDGE
				{
					motor_stop();
					g_joint_configuration.calibration_table_2[g_joint_status.mc_current_electric_rotation / g_joint_configuration.calibration_sector_size] = g_ma730.angle;
					g_max_electric_rotation_cw 	= g_joint_status.mc_current_electric_rotation; // max electric rotation counter

					g_max_encoder_position = g_joint_status.mc_current_motor_position_multiturn; // max encoder value
					g_fsm_status.state = FSM_CALIBRATION_PHASE_3;

				}
				else
				{
					motor_start(SPEED_MODE, g_calibration_speed);
				}

				break;
			}

			case FSM_CALIBRATION_PHASE_3:
			{
				if (g_joint_status.mc_current_electric_rotation % g_joint_configuration.calibration_sector_size == (g_joint_configuration.calibration_sector_size - 1) &&
						g_joint_configuration.calibration_table_2[g_joint_status.mc_current_electric_rotation / g_joint_configuration.calibration_sector_size] == 0)
				{
					g_joint_configuration.calibration_table_2[g_joint_status.mc_current_electric_rotation / g_joint_configuration.calibration_sector_size] = g_ma730.angle;
				}

				if (motor_reach_torque_limit()) // REACH MINIMUM EDGE
				{
					motor_stop();
					g_joint_configuration.calibration_table_1[g_joint_status.mc_current_electric_rotation / g_joint_configuration.calibration_sector_size] = g_ma730.angle;
					g_fsm_status.state = FSM_CALIBRATION_PHASE_4;

				}
				else
				{
					motor_start(SPEED_MODE, -1 * g_calibration_speed);
				}

				break;
			}

			case FSM_CALIBRATION_PHASE_4:
			{
				// Sprawdzenie tablicy kalibracyjnej
				if (!check_calibration_data_cw(g_max_electric_rotation_cw / g_joint_configuration.calibration_sector_size) ||
					!check_calibration_data_ccw(g_max_electric_rotation_cw / g_joint_configuration.calibration_sector_size))
				{
					g_fsm_status.state = FSM_CALIBRATION_PHASE_2;
					g_calibration_state = CALIBRATION_TABLE_CONTAINS_ZEROES;
				}
				else
				{
					g_max_electric_rotation_ccw = g_joint_status.mc_current_electric_rotation; // Should be 0 right now
					g_center_encoder_position = (g_max_encoder_position - g_min_encoder_position + 1) / 2 + g_min_encoder_position;

					g_joint_configuration.number_of_sectors = (uint16_t) (g_max_electric_rotation_cw / g_joint_configuration.calibration_sector_size);
					g_joint_configuration.reachable_electrical_rotations = g_max_electric_rotation_cw;
					g_calibration_state = CALIBRATION_OK;
					g_fsm_status.state = FSM_CALIBRATION_PHASE_5;
				}
				break;
			}

			case FSM_CALIBRATION_PHASE_5:
			{
				if (motor_in_position(g_center_encoder_position))
				{
					g_fsm_status.state = FSM_CALIBRATION_PHASE_6;
					motor_start(SPEED_MODE, 0);
					motor_stop();

					g_joint_configuration.zero_electric_rotation = g_joint_status.mc_current_electric_rotation;
//					g_joint_configuration.zero_electric_position = (uint16_t) (g_motor_status.current_electric_position);
					g_joint_configuration.zero_electric_position = (int16_t) (g_joint_status.mc_current_electric_position);
				}
				else
				{
					motor_start(SPEED_MODE, g_calibration_speed);
				}

				if (motor_reach_torque_limit()) // REACH EDGE - FAILURE
				{
					motor_start(SPEED_MODE, 0);
					motor_stop();
					g_calibration_state = MISSED_CENTER_POSITION;
	//						g_fsm_status.state = FSM_STOPPED_WITH_ERRORS;
					FSM_Activate_State(FSM_FAULT_REACTION_ACTIVE);

				}

				break;
			}
			case FSM_CALIBRATION_PHASE_6:
			{
				volatile uint32_t error;

				HAL_TIM_Base_Stop_IT(&htim6); // Disable 10 kHz timer

				uint64_t data;

				HAL_FLASH_Unlock();

				FLASH_EraseInitTypeDef EraseInitStruct;
				EraseInitStruct.TypeErase 	= FLASH_TYPEERASE_PAGES;
				EraseInitStruct.Banks 		= FLASH_BANK_1;
				EraseInitStruct.Page 		= (g_flash_address_configuration & 0x07FFFFFF) / FLASH_PAGE_SIZE;
				EraseInitStruct.NbPages 	= 2; // 1 - 2kB
				uint32_t PageError;

				if (HAL_FLASHEx_Erase(&EraseInitStruct, &PageError) != HAL_OK)
				{
					error = HAL_FLASH_GetError ();
				}

				// Configuration
				data = (g_joint_configuration.gear_ratio << 16) | g_joint_configuration.pole_pairs;
				if (HAL_FLASH_Program(FLASH_TYPEPROGRAM_DOUBLEWORD, g_flash_address_configuration, data) != HAL_OK)
				{
					error = HAL_FLASH_GetError ();
				}

				data = (g_joint_configuration.reachable_electrical_rotations << 16) | g_joint_configuration.calibration_sector_size;
				if (HAL_FLASH_Program(FLASH_TYPEPROGRAM_DOUBLEWORD, g_flash_address_configuration + 8, data) != HAL_OK)
				{
					error = HAL_FLASH_GetError ();
				}

				data = (g_joint_configuration.calibration_sector_size << 16) | g_joint_configuration.number_of_sectors;
				if (HAL_FLASH_Program(FLASH_TYPEPROGRAM_DOUBLEWORD, g_flash_address_configuration + 16, data) != HAL_OK)
				{
					error = HAL_FLASH_GetError ();
				}

				uint16_t * temp = (uint16_t *) &g_joint_configuration.zero_electric_position;
				data = (g_joint_configuration.zero_electric_rotation << 16) | (* temp) ;
				if (HAL_FLASH_Program(FLASH_TYPEPROGRAM_DOUBLEWORD, g_flash_address_configuration + 24, data) != HAL_OK)
				{
					error = HAL_FLASH_GetError ();
				}

				for(int i = 0; i < g_joint_configuration.number_of_sectors; i++ )
				{
					data = g_joint_configuration.calibration_table_1[i] << 16 | g_joint_configuration.calibration_table_2[i];
					if (HAL_FLASH_Program(FLASH_TYPEPROGRAM_DOUBLEWORD, g_flash_address_calibration_table + i * 8, data) != HAL_OK)
					{
						error = HAL_FLASH_GetError ();
					}
				}

				HAL_FLASH_Lock();

				g_joint_configuration.calibration_state = JOINT_CALIBRATED;

				FSM_Activate_State(FSM_INIT); // CALIBRATION FINISHED - GO TO INIT STATE

				HAL_TIM_Base_Start_IT(&htim6); // Enable 10 kHz timer
				break;
			}

			case FSM_START:
			{
				HAL_TIM_Base_Stop_IT(&htim6); // Enable 10 kHz timer

				g_joint_configuration.pole_pairs = POLE_PAIRS;
				g_joint_configuration.gear_ratio = GEAR_RATIO;

				// Read DIP switches
				g_joint_configuration.dip1 = (HAL_GPIO_ReadPin(GPIOC, DIP1_Pin) == GPIO_PIN_RESET) ? (0) : (1);
				g_joint_configuration.dip2 = (HAL_GPIO_ReadPin(GPIOC, DIP2_Pin) == GPIO_PIN_RESET) ? (0) : (1);
				g_joint_configuration.dip3 = (HAL_GPIO_ReadPin(GPIOB, DIP3_Pin) == GPIO_PIN_RESET) ? (0) : (1);
				g_joint_configuration.dip4 = (HAL_GPIO_ReadPin(GPIOB, DIP4_Pin) == GPIO_PIN_RESET) ? (0) : (1);

				// Configure CAN ID
				g_joint_configuration.can_node_id = (uint8_t) (g_joint_configuration.dip2 << 2 | g_joint_configuration.dip3 << 1 | g_joint_configuration.dip4);

				// disable dip4 allow multiturn
	//					g_joint_configuration.working_area_constrain = g_joint_configuration.dip1;
//				g_joint_configuration.working_area_constrain = true;
	//	  			g_joint_configuration.ma730_exists = _dip1;

				// FDCAN
				HAL_FDCAN_ConfigTxDelayCompensation(&hfdcan1, 10, 0);
				HAL_FDCAN_EnableTxDelayCompensation(&hfdcan1);

				// CAN FILTERS
				FDCAN_FilterTypeDef   can_filter_config_0; // BROADCAST
				can_filter_config_0.IdType = FDCAN_STANDARD_ID;
				can_filter_config_0.FilterIndex = 0;
				can_filter_config_0.FilterType = FDCAN_FILTER_MASK;
				can_filter_config_0.FilterConfig = FDCAN_FILTER_TO_RXFIFO0;
				can_filter_config_0.FilterID1 = 0x0F0;
				can_filter_config_0.FilterID2 = 0x70F ;
				HAL_FDCAN_ConfigFilter(&hfdcan1, &can_filter_config_0); //Initialize CAN Filter

				FDCAN_FilterTypeDef   can_filter_config_1; // UNICAST
				can_filter_config_1.IdType = FDCAN_STANDARD_ID;
				can_filter_config_1.FilterIndex = 1;
				can_filter_config_1.FilterType = FDCAN_FILTER_MASK;
				can_filter_config_1.FilterConfig = FDCAN_FILTER_TO_RXFIFO0;
				can_filter_config_1.FilterID1 = 0x100 + g_joint_configuration.can_node_id;
				can_filter_config_1.FilterID2 = 0x70F;
				HAL_FDCAN_ConfigFilter(&hfdcan1, &can_filter_config_1); //Initialize CAN Filter

				HAL_FDCAN_ConfigGlobalFilter(&hfdcan1, 3, 3, FDCAN_FILTER_REMOTE, FDCAN_REJECT_REMOTE);
				HAL_FDCAN_Start(&hfdcan1); //Initialize CAN Bus
				HAL_FDCAN_ActivateNotification(&hfdcan1, FDCAN_IT_RX_FIFO0_NEW_MESSAGE, 0);// Initialize CAN Bus Rx Interrupt
				HAL_FDCAN_EnableISOMode(&hfdcan1);

				// Read configuration from FLASH
				Flash_Read_Data(g_flash_address_configuration, (uint32_t *) g_calibration_config, 8);

				g_joint_configuration.calibration_table_size 			= g_calibration_config[8]; // FIXME !!!!

				if (g_joint_configuration.calibration_table_size > 0 && g_joint_configuration.calibration_table_size < 65535) {
					// Read joint configuration from FLASH
					g_joint_configuration.pole_pairs 						= g_calibration_config[0];
					g_joint_configuration.gear_ratio 						= g_calibration_config[1];
					g_joint_configuration.calibration_sector_size 			= g_calibration_config[4];
					g_joint_configuration.reachable_electrical_rotations	= g_calibration_config[5];
					g_joint_configuration.number_of_sectors 				= g_calibration_config[8];
					g_joint_configuration.zero_electric_position 			= (uint8_t) g_calibration_config[12];
					g_joint_configuration.zero_electric_rotation 			= g_calibration_config[13];

					// Read calibration table from FLASH
					//	for (int i = 0; i <= g_joint_configuration.calibration_table_size / 2 + 1; i++) {
					for (int i = 0; i <= g_joint_configuration.calibration_table_size; i++) {
						Flash_Read_Data (g_flash_address_calibration_table + i * 8, (uint32_t *) g_data, 1);
						g_joint_configuration.calibration_table_1[i]	= g_data[0] >> 16;
						g_joint_configuration.calibration_table_2[i] 	= g_data[0];
					}

					g_joint_configuration.maximum_electrical_rotations = g_joint_configuration.gear_ratio * g_joint_configuration.pole_pairs;

					g_joint_configuration.calibration_state = JOINT_CALIBRATED;

				}
				g_joint_configuration.joint_working_area = M_PI * 165.0 / 180.0;

//				g_node_status.security = SECURITY_DISABLED;
//				g_node_status.hartbeat = HEARTBEAT_DISABLED;
//				g_node_status.node_type = JOINT_TYPE;

				FSM_Activate_Transition(FSM_TRANSITION_START_TO_INIT);

				HAL_TIM_Base_Start_IT(&htim6); // Enable 10 kHz timer

				break;
			}

			case FSM_TRANSITION_START_TO_INIT:
			{
				FSM_Activate_State(FSM_INIT);
				break;
			}

			case FSM_INIT:
			{
				if (g_joint_configuration.ma730_enabled == true && g_ma730.started == false)
				{
					g_ma730.started = true;

					HAL_GPIO_WritePin(MA730_CS_GPIO_Port, MA730_CS_Pin, GPIO_PIN_RESET);

					HAL_SPI_TransmitReceive_IT(&hspi2, (uint8_t * ) &g_spi_tx_data, (uint8_t * ) &g_spi_rx_data, 1);
				}

				if (g_joint_configuration.ma730_enabled == false && g_ma730.started == true)
				{
					g_ma730.started = false;

				}

				break;
			}

			case FSM_TRANSITION_INIT_TO_READY_TO_OPERATE:
			{
				// Check the calibration
				// If joint is not calibrated go to failure
				FSM_Activate_State(FSM_READY_TO_OPERATE);
				break;
			}

			case FSM_READY_TO_OPERATE:
			{
				motor_stop();
				break;
			}

			case FSM_TRANSITION_READY_TO_OPERATE_TO_OPERATION_ENABLE:
			{
				FSM_Activate_State(FSM_OPERATION_ENABLE);
				break;
			}

			case FSM_TRANSITION_OPERATION_ENABLE_TO_READY_TO_OPERATE:
			{
				FSM_Activate_State(FSM_READY_TO_OPERATE);
				motor_stop();
				break;
			}

			case FSM_TRANSITION_INIT_TO_CALIBRATION_PHASE_0:
			{
				FSM_Activate_State(FSM_CALIBRATION_PHASE_0);
				break;
			}

			case FSM_OPERATION_ENABLE:
			{

				int16_t goal = 0;

				switch (g_app_command.working_mode)
				{
					case TORQUE_MODE:
					{
						goal = g_app_command._motor_torque;
						break;
					}

					case SPEED_MODE:
					{
						goal = g_app_command._motor_speed;
						break;
					}
				}

				if (g_joint_configuration.working_area_constrain_enabled)
				{
					switch (g_joint_status.current_joint_position)
					{
						case POSITION_UNDER_WORKING_AREA: // Accept only positive torque
							if (goal < 0)
							{
								motor_stop();
							}
							else
							{
								motor_start(g_app_command.working_mode, goal);
							}
							break;

						case POSITION_IN_WORKING_AREA:
							motor_start(g_app_command.working_mode, goal);
							break;

						case POSITION_OVER_WORKING_AREA: // Accept only negative torque
							if (goal > 0)
							{
								motor_stop();
							}
							else
							{
								motor_start(g_app_command.working_mode, goal);
							}
							break;
					}

				}
				else
				{
					motor_start(g_app_command.working_mode, goal);
				}

				break;

			}

			case FSM_TRANSITION_FAULT_TO_INIT:
			{
				MC_AcknowledgeFaultMotor1();
				g_joint_status.errors = 0;
				FSM_Activate_State(FSM_INIT);
				break;
			}

			case FSM_TRANSITION_FAULT_REACTION_ACTIVE_TO_FAULT:
			{
				motor_stop();
				FSM_Activate_State(FSM_FAULT);
				break;
			}

			case FSM_FAULT_REACTION_ACTIVE:
			{
				motor_stop();
				FSM_Activate_Transition(FSM_TRANSITION_FAULT_REACTION_ACTIVE_TO_FAULT);
				break;
			}

			case FSM_FAULT:
			{
				motor_stop();
				break;
			}

			default:
			{
				FSM_Activate_State(FSM_FAULT_REACTION_ACTIVE);
				break;
			}
		}
		g_counters.timer7++;
	}
}

void HAL_FDCAN_RxFifo0Callback(FDCAN_HandleTypeDef *hfdcan1, uint32_t RxFifo0ITs)
{

	if((RxFifo0ITs & FDCAN_IT_RX_FIFO0_NEW_MESSAGE) != 0)
	{
		// RETRIEVE CAN MESSAGE -------------------------------------------------------------------------
		HAL_FDCAN_GetRxMessage(hfdcan1, FDCAN_RX_FIFO0, &can_rx_header, can_rx_data);
		g_counters.can_rx_counter++;

		// RESET SAFE TIMER -----------------------------------------------------------------------------
//		HAL_TIM_Base_Stop(&htim6);
//		TIM6->CNT = 0;
//		HAL_TIM_Base_Start_IT(&htim6);

		bool l_send_response = true;
		uint8_t l_cmd 	= (can_rx_header.Identifier & 0x0F0) >> 4; // Ustalenie polecenie
		bool l_unicast 	= (can_rx_header.Identifier & 0x100) >> 8; // Ustalenie typu transmisji: BROADCAST|UNICAST

		// CAN TRANSMITION CONFIGURATION
		can_tx_header.Identifier = can_rx_header.Identifier | g_joint_configuration.can_node_id | 0x01 << 9;
		can_tx_header.IdType = FDCAN_STANDARD_ID;
		can_tx_header.TxFrameType = FDCAN_DATA_FRAME;
		can_tx_header.DataLength = FDCAN_DLC_BYTES_12;
		can_tx_header.ErrorStateIndicator = FDCAN_ESI_ACTIVE;
		can_tx_header.BitRateSwitch = FDCAN_BRS_ON;
		can_tx_header.FDFormat = FDCAN_FD_CAN;
		can_tx_header.TxEventFifoControl = FDCAN_NO_TX_EVENTS;
		can_tx_header.MessageMarker = 0;

		// UPDATE JOINT INFO ----------------------------------------------------------------------------
		uint8_t numer_w_szeregu = 0;
		uint8_t dlugosc_danych_polecenia = 0;

		if (!l_unicast)
		{
			numer_w_szeregu = g_joint_configuration.can_node_id; // ???
		}

		switch (l_cmd) {

			case 0x0: // Wykonaj akcję
			{
				dlugosc_danych_polecenia = 2;
				// int16_t w zaleznosci od trybu pracy - torque, speed
				uint8_t offset = dlugosc_danych_polecenia * numer_w_szeregu;

				int16_t goal;
				goal  = can_rx_data[offset] << 8;
				goal += can_rx_data[offset + 1];

				// GOAL TORQUE
				// -------------------------------------------------------------------------------------------------
				// recalculate torque goal data from CAN to floats
				g_app_command.joint_torque = ((float) goal * MAX_TORQUE_THROUGH_CAN) / (float) INT16_MAX; // convert from int16 to float
				g_app_command.motor_torque = g_app_command.joint_torque / g_joint_configuration.gear_ratio;

				// recalculate torque goal data from floats to MC
				g_app_command._motor_torque	= (((float) g_app_command.motor_torque) * INT16_MAX) / (MAX_READABLE_CURRENT * KT);  // convert from float to s16A

				// -------------------------------------------------------------------------------------------------
				// Recalculate data from MC to Floats
				Update_Data_From_MC();
				// recalculate date from
//				// POSITION
//				g_joint_status.f_current_motor_position = (double) g_joint_status.mc_current_motor_position_multiturn / ENCODER_M1.PulseNumber;
//				g_joint_status.f_current_joint_position = (double) g_joint_status.f_current_motor_position / g_joint_configuration.gear_ratio;
//
//				// SPEED
//				g_joint_status.f_current_motor_speed = g_joint_status.mc_current_motor_speed * 6 * M_TWOPI / 60;
//				g_joint_status.f_current_joint_speed = g_joint_status.f_current_motor_speed / g_joint_configuration.gear_ratio;
//
//				// TORQUE
//				// recalculate_torques
//				float temp_torque = 0;
//				for (int i = 0; i < CURRENT_TORQUE_DATA_SIZE; i++)
//				{
//					temp_torque += (float) g_joint_status._current_torque_data[i];
//				}
//
//				g_joint_status.f_current_motor_torque			= (((float) (temp_torque / CURRENT_TORQUE_DATA_SIZE)) / INT16_MAX) * 33.0 * KT;
//				g_joint_status.f_current_joint_torque			= g_joint_status.f_current_motor_torque * g_joint_configuration.gear_ratio;

				// -------------------------------------------------------------------------------------------------
				// Recalculate data from floats to CAN
				int32_t l_joint_position_in_s32degree = (int32_t) (g_joint_status.f_current_joint_position * (UINT32_MAX / M_TWOPI));

				int16_t l_speed_in_dpp = g_joint_status.f_current_joint_speed * (float) INT16_MAX / M_TWOPI;

				int16_t l_current_torque_in_s16a = (g_joint_status.f_current_joint_torque / MAX_TORQUE_THROUGH_CAN) * (float) INT16_MAX;
				if (g_app_command.motor_torque < 0)
				{
					l_current_torque_in_s16a = -l_current_torque_in_s16a;
				}

				// -------------------------------------------------------------------------------------------------
				can_tx_data[0] 	= l_joint_position_in_s32degree >> 24;
				can_tx_data[1] 	= l_joint_position_in_s32degree >> 16;
				can_tx_data[2] 	= l_joint_position_in_s32degree >> 8;
				can_tx_data[3] 	= l_joint_position_in_s32degree;
				can_tx_data[4] 	= l_speed_in_dpp >> 8;
				can_tx_data[5] 	= l_speed_in_dpp;
				can_tx_data[6] 	= l_current_torque_in_s16a >> 8;
				can_tx_data[7] 	= l_current_torque_in_s16a;
				can_tx_data[8] 	= (uint8_t) g_joint_status.f_current_motor_temperature; // temp FIXME
				can_tx_data[9] 	= FSM_Get_State(); // FSM
				can_tx_data[10]	= g_joint_status.mc_current_faults_motor;
				can_tx_data[11] = g_joint_status.mc_occured_faults_motor;
				can_tx_data[12] = g_joint_status.errors;
				can_tx_data[13] = g_joint_status.warnings;

				can_tx_header.DataLength = FDCAN_DLC_BYTES_16;

				break;
			}

			case 0x1: // Zmien stan FSM
			{
				dlugosc_danych_polecenia = 1;
				// uint8_t - FSM
				uint8_t offset = dlugosc_danych_polecenia * numer_w_szeregu;

				FSM_Set_State(can_rx_data[offset]);

				can_tx_data[0] = FSM_Get_State();

				can_tx_header.DataLength = FDCAN_DLC_BYTES_1;
				break;
			}

			case 0xF: // Konfiguracja
			{
				dlugosc_danych_polecenia = 2;
				// uint8_t tryb pracy
				uint8_t offset = dlugosc_danych_polecenia * numer_w_szeregu;
				if (FSM_Get_State() == FSM_INIT) {
					g_app_command.working_mode = can_rx_data[offset];
					g_joint_configuration.working_area_constrain_enabled = (can_rx_data[offset + 1] & 0x01);
					g_joint_configuration.ma730_enabled = (can_rx_data[offset + 1] & 0x02) >> 1;
					can_tx_data[0] = 1;
				}
				else
				{
					can_tx_data[0] = 0;
				}

				can_tx_header.DataLength = FDCAN_DLC_BYTES_1;
				break;
			}

			default:
			{
				l_send_response = false;

			}

		}

		//	SEND FRAME VIA FD CAN -------------------------------------------------------------------------------
		if (HAL_FDCAN_AddMessageToTxFifoQ(hfdcan1, &can_tx_header, can_tx_data) == HAL_OK && l_send_response)
		{
			g_counters.can_tx_counter++;
		}

		// clear global rx and tx buffer
		for (int i = 0; i < 24; i++)
		{
			can_rx_data[i]	= 0;
			can_tx_data[i]	= 0;
		}
	}
}

bool FSM_Activate_State(FSM_State_t new_state)
{
	g_fsm_status.state = new_state;
	return true;
}

bool FSM_Activate_Transition(FSM_State_t new_transition)
{
	g_fsm_status.state = new_transition;
	return true;
}

bool FSM_Set_State(FSM_State_t new_state) // FIXME running transition should block changing state to new one - add flag transition is running
{

	switch (new_state)
	{
//#if defined CALIBRATION
//#else
		case FSM_START:
		{
			break;
		}

		case FSM_INIT:
		{
			if (FSM_Get_State() == FSM_START)
			{
				return FSM_Activate_Transition(FSM_TRANSITION_START_TO_INIT);
			}

			if (FSM_Get_State() == FSM_FAULT)
			{
				return FSM_Activate_Transition(FSM_TRANSITION_FAULT_TO_INIT);
			}
			break;
		}

		case FSM_READY_TO_OPERATE:
		{

			if (FSM_Get_State() == FSM_INIT)
			{
				return FSM_Activate_Transition(FSM_TRANSITION_INIT_TO_READY_TO_OPERATE);
			}

			if (FSM_Get_State() == FSM_OPERATION_ENABLE)
			{
				return FSM_Activate_Transition(FSM_TRANSITION_OPERATION_ENABLE_TO_READY_TO_OPERATE);
			}

			break;
		}

		case FSM_OPERATION_ENABLE:
		{
			if (FSM_Get_State() == FSM_READY_TO_OPERATE)
			{
				return FSM_Activate_Transition(FSM_TRANSITION_READY_TO_OPERATE_TO_OPERATION_ENABLE);
			}
			break;
		}

		case FSM_CALIBRATION_PHASE_0:
		{

			if (FSM_Get_State() == FSM_INIT)
			{
				return FSM_Activate_Transition(FSM_TRANSITION_INIT_TO_CALIBRATION_PHASE_0);
			}

			break;
		}

		case FSM_FAULT_REACTION_ACTIVE:
		{
			if (FSM_Get_State() != FSM_START)
			{
				return FSM_Activate_Transition(FSM_TRANSITION_FAULT_REACTION_ACTIVE_TO_FAULT);
			}
			break;
		}

		case FSM_FAULT:
		{
			if (FSM_Get_State() == FSM_READY_TO_OPERATE)
			{
				return FSM_Activate_Transition(FSM_TRANSITION_READY_TO_OPERATE_TO_OPERATION_ENABLE);
			}
			break;
		}

		default:
		{
			break;
		}
//#endif
	}

	return false;
}

FSM_State_t FSM_Get_State(void)
{
	return g_fsm_status.state;
}

//void MA730_ReadRegister(uint8_t reg_number) {
//	uint16_t send_data      = 0b010 << 13 | (reg_number & (0b00011111)) << 8 ;
//
//	uint16_t angle_value    = 0;
//	uint16_t register_value = 0;
//
//	for (uint16_t i = 0; i < 24; i++) NOP;  // wait about 150ns
//
//	HAL_GPIO_WritePin(MA730_CS_GPIO_Port, MA730_CS_Pin, GPIO_PIN_RESET);
//
//	for (uint16_t i = 0; i < 130; i++) NOP;  // wait about 80ns
//
//	// SEND READ REGISTER COMMAND - RECEIVE READ ANGLE RESULT
//	HAL_SPI_TransmitReceive(&hspi2, (uint8_t * ) &send_data, (uint8_t * ) &angle_value, 1, 1);
//
//	HAL_GPIO_WritePin(MA730_CS_GPIO_Port, MA730_CS_Pin, GPIO_PIN_SET);
//
//	for (uint16_t i = 0; i < 120; i++) NOP;  // wait about 750ns
//
//	HAL_GPIO_WritePin(MA730_CS_GPIO_Port, MA730_CS_Pin, GPIO_PIN_RESET);
//
//	for (uint16_t i = 0; i < 13; i++) NOP;  // wait about 80ns
//
//	send_data      = 0x0000;
//
//	// SEND READ ANGLE COMMAND - RECEIVE READ REGISTER RESULT
//	HAL_SPI_TransmitReceive(&hspi2, (uint8_t * ) &send_data, (uint8_t * ) &register_value, 1, 1);
//
////	g_MA730_read_buffer = register_value >> 8;
//
//	HAL_GPIO_WritePin(MA730_CS_GPIO_Port, MA730_CS_Pin, GPIO_PIN_SET);
//
//	for (uint16_t i = 0; i < 120; i++) NOP;  // wait about 750ns
//
//	g_ma730.angle = (angle_value >> 2) & 0b0011111111111111;
//
//	register_value = register_value >> 8;
//	switch (reg_number)
//	{
//		case 0x00:
//		{
//			g_ma730.z0 = (uint8_t) register_value;
//			break;
//		}
//		case 0x01:
//		{
//			g_ma730.z1 = (uint8_t) register_value;
//			break;
//		}
//		case 0x02:
//		{
//			g_ma730.bct = (uint8_t) register_value;
//			break;
//		}
//		case 0x03:
//		{
//			g_ma730.ety = ((uint8_t) register_value & 0b00000010) >> 1;
//			g_ma730.etx = ((uint8_t) register_value & 0b00000001);
//			break;
//		}
//		case 0x04:
//		{
//			g_ma730.ppt0 = ((uint8_t) register_value & 0b11000000) >> 6;
//			g_ma730.ilip = ((uint8_t) register_value & 0b00111100) >> 2;
//			break;
//		}
//		case 0x05:
//		{
//			g_ma730.ppt1 = (uint8_t) register_value;
//			break;
//		}
//		case 0x06:
//		{
//			g_ma730.mglt = ((uint8_t) register_value & 0b11100000) >> 5;
//			g_ma730.mght = ((uint8_t) register_value & 0b00011100) >> 2;
//			break;
//		}
//		case 0x09:
//		{
//			g_ma730.rd = (uint8_t) register_value >> 7;
//			break;
//		}
//		case 0x1b:
//		{
//			g_ma730.mgl = ((uint8_t) register_value & 0b01000000) >> 6;
//			g_ma730.mgh = ((uint8_t) register_value & 0b10000000) >> 7;
//			break;
//		}
//		default:
//		{
//			break;
//		}
//	}
//
////	if (g_counter_1hz > 1) // wait 1 sec to analyse data
////	{
////		g_motor_status.ma730_is_running = true;
////		g_motor_status.previous_ma730_value = g_motor_status.current_ma730_value;
////		g_motor_status.current_ma730_value = (g_MA730_read_buffer >> 2) & 0b0011111111111111;
////	}
//
////	if (g_ma730.mgl || g_ma730.mgh) // not proper magnetic field strentgh
////	{
////		g_motor_status.warnings |= JOINT_MA730_NOT_PROPER_MAGNETOC_FIELD;
////	}
////	else
////	{
////		g_motor_status.warnings = g_motor_status.warnings & (0xFF ^ JOINT_MA730_NOT_PROPER_MAGNETOC_FIELD);
////
////	}
//
//}

//void MA730_ReadAngle() {
//	uint16_t send_data      = 0x0000 ;
//
//	uint16_t angle_value    = 0;
//
////	for (uint16_t i = 0; i < 24; i++) NOP;  // wait about 150ns
//
//	HAL_GPIO_WritePin(MA730_CS_GPIO_Port, MA730_CS_Pin, GPIO_PIN_RESET);
//
////	for (uint16_t i = 0; i < 13; i++) NOP;  // wait about 80ns
//
//	// SEND READ REGISTER COMMAND - RECEIVE READ ANGLE RESULT
//	HAL_SPI_TransmitReceive(&hspi2, (uint8_t * ) &send_data, (uint8_t * ) &angle_value, 1, 1);
//
//	HAL_GPIO_WritePin(MA730_CS_GPIO_Port, MA730_CS_Pin, GPIO_PIN_SET);
//
////	for (uint16_t i = 0; i < 12; i++) NOP;  // wait about 80ns
//
//	g_ma730.angle = (angle_value >> 2) & 0b0011111111111111;
//
//}

// Current FDBK
void R3_2_GetPhaseCurrents( PWMC_Handle_t * pHdl, ab_t * Iab )
{
#if defined (__ICCARM__)
  #pragma cstat_disable = "MISRAC2012-Rule-11.3"
#endif /* __ICCARM__ */
  PWMC_R3_2_Handle_t * pHandle = ( PWMC_R3_2_Handle_t * )pHdl;
#if defined (__ICCARM__)
  #pragma cstat_restore = "MISRAC2012-Rule-11.3"
#endif /* __ICCARM__ */
  TIM_TypeDef * TIMx = pHandle->pParams_str->TIMx;

  uint8_t Sector;
  int32_t Aux;
  uint32_t ADCDataReg1;
  uint32_t ADCDataReg2;

  Sector = ( uint8_t )pHandle->_Super.Sector;
  ADCDataReg1 = *pHandle->pParams_str->ADCDataReg1[Sector];
  ADCDataReg2 = *pHandle->pParams_str->ADCDataReg2[Sector];

  /* disable ADC trigger source */
  //LL_TIM_CC_DisableChannel(TIMx, LL_TIM_CHANNEL_CH4);
  LL_TIM_SetTriggerOutput(TIMx, LL_TIM_TRGO_RESET);

  switch ( Sector )
  {
    case SECTOR_4:
    case SECTOR_5:
      /* Current on Phase C is not accessible     */
      /* Ia = PhaseAOffset - ADC converted value) */
//      Aux = ( int32_t )( pHandle->PhaseAOffset ) - ( int32_t )( ADCDataReg1 );
		Aux = (int32_t) (ADCDataReg1) - (int32_t) (pHandle->PhaseAOffset);

      /* Saturation of Ia */
      if ( Aux < -INT16_MAX )
      {
        Iab->a = -INT16_MAX;
      }
      else  if ( Aux > INT16_MAX )
      {
        Iab->a = INT16_MAX;
      }
      else
      {
        Iab->a = ( int16_t )Aux;
      }

      /* Ib = PhaseBOffset - ADC converted value) */
//      Aux = ( int32_t )( pHandle->PhaseBOffset ) - ( int32_t )( ADCDataReg2 );
      Aux = ( int32_t )( ADCDataReg2 ) - ( int32_t )( pHandle->PhaseBOffset );

      /* Saturation of Ib */
      if ( Aux < -INT16_MAX )
      {
        Iab->b = -INT16_MAX;
      }
      else  if ( Aux > INT16_MAX )
      {
        Iab->b = INT16_MAX;
      }
      else
      {
        Iab->b = ( int16_t )Aux;
      }
      break;

    case SECTOR_6:
    case SECTOR_1:
      /* Current on Phase A is not accessible     */
      /* Ib = PhaseBOffset - ADC converted value) */
//      Aux = ( int32_t )( pHandle->PhaseBOffset ) - ( int32_t )( ADCDataReg1 );
    	Aux = ( int32_t )( ADCDataReg1 ) - ( int32_t )( pHandle->PhaseBOffset );

      /* Saturation of Ib */
      if ( Aux < -INT16_MAX )
      {
        Iab->b = -INT16_MAX;
      }
      else  if ( Aux > INT16_MAX )
      {
        Iab->b = INT16_MAX;
      }
      else
      {
        Iab->b = ( int16_t )Aux;
      }

      /* Ia = -Ic -Ib */
//      Aux = ( int32_t )( ADCDataReg2 ) - ( int32_t )( pHandle->PhaseCOffset ); /* -Ic */
      Aux = ( int32_t )( pHandle->PhaseCOffset ) - ( int32_t )( ADCDataReg2 ); /* Ic reversed */
      Aux -= ( int32_t )Iab->b;             /* Ia  */

      /* Saturation of Ia */
      if ( Aux > INT16_MAX )
      {
        Iab->a = INT16_MAX;
      }
      else  if ( Aux < -INT16_MAX )
      {
        Iab->a = -INT16_MAX;
      }
      else
      {
        Iab->a = ( int16_t )Aux;
      }
      break;

    case SECTOR_2:
    case SECTOR_3:
      /* Current on Phase B is not accessible     */
      /* Ia = PhaseAOffset - ADC converted value) */
//      Aux = ( int32_t )( pHandle->PhaseAOffset ) - ( int32_t )( ADCDataReg1 );
    	Aux = ( int32_t )( ADCDataReg1 ) - ( int32_t )( pHandle->PhaseAOffset );

      /* Saturation of Ia */
      if ( Aux < -INT16_MAX )
      {
        Iab->a = -INT16_MAX;
      }
      else  if ( Aux > INT16_MAX )
      {
        Iab->a = INT16_MAX;
      }
      else
      {
        Iab->a = ( int16_t )Aux;
      }

      /* Ib = -Ic -Ia */
//      Aux = ( int32_t )( ADCDataReg2 ) - ( int32_t )( pHandle->PhaseCOffset ); /* -Ic */
      Aux = ( int32_t )( pHandle->PhaseCOffset ) - ( int32_t )( ADCDataReg2 ); /* -Ic */
      Aux -= ( int32_t )Iab->a;             /* Ib */

      /* Saturation of Ib */
      if ( Aux > INT16_MAX )
      {
        Iab->b = INT16_MAX;
      }
      else  if ( Aux < -INT16_MAX )
      {
        Iab->b = -INT16_MAX;
      }
      else
      {
        Iab->b = ( int16_t )Aux;
      }
      break;

    default:
      break;
  }

  pHandle->_Super.Ia = Iab->a;
  pHandle->_Super.Ib = Iab->b;
  pHandle->_Super.Ic = -Iab->a - Iab->b;
}
/* USER CODE END 4 */

void Error_Handler(void)
{
  __disable_irq();
  while (1)
  {
  }
}

/************************ (C) COPYRIGHT STMicroelectronics *****END OF FILE****/
